AUTOSAR XML (schema 00047)
package /DBCImport/CANTP
  can tp config CanTpConfig_BCAN: communication-cluster=BCAN, can-tp-ecu=WPC
    can tp channel CanTpChannel0: channel-id=0, channel-mode=HALF-DUPLEX-MODE
    can tp channel CanTpChannel1: channel-id=1, channel-mode=HALF-DUPLEX-MODE
    tp-connections:
      addressing-format=STANDARD, can-tp-channel=CanTpChannel0, data-pdu=NPdu_BCAN_WPC_GST, flow-control-pdu=NPdu_BCAN_GST_WPC, max-block-size=0, padding-activation=true, ta-type=PHYSICAL-CAN-FD, tp-sdu=DcmIPdu_BCAN_WPC_GST
      addressing-format=STANDARD, can-tp-channel=CanTpChannel0, data-pdu=NPdu_BCAN_GST_WPC, flow-control-pdu=NPdu_BCAN_WPC_GST, max-block-size=0, padding-activation=true, ta-type=PHYSICAL-CAN-FD, tp-sdu=DcmIPdu_BCAN_GST_WPC
      addressing-format=STANDARD, can-tp-channel=CanTpChannel1, data-pdu=NPdu_BCAN_GST_ALL, max-block-size=0, padding-activation=true, ta-type=FUNCTIONAL-CAN-FD, tp-sdu=DcmIPdu_BCAN_GST_ALL
    can tp node WPC: connector=Conn_WPC_BCAN
package /DBCImport/NMCONFIG
  nm config NmConfig_BCAN
    can nm cluster CanNmCluster_BCAN: communication-cluster=BCAN, nm-pnc-participation=true, nm-msg-cycle-time=0.1, nm-network-timeout=1.0, nm-repeat-message-time=1.2, nm-wait-bus-sleep-time=1.5
      can nm node CanNmNode_BCAN:
        nm-node-id=158
        rx-nm-pdu=[NmPdu_BCAN_NM_SHVU_CCS_FD, NmPdu_BCAN_NM_ARS_FD, NmPdu_BCAN_NM_WPC2_FD, NmPdu_BCAN_NM_SCM_FD, NmPdu_BCAN_NM_SHVU_FRNT_FD, NmPdu_BCAN_NM_FLLR_FD, NmPdu_BCAN_NM_GW_SAU_DRV_FD, NmPdu_BCAN_NM_ATS_FD, NmPdu_BCAN_NM_PSB_FD, NmPdu_BCAN_NM_GW_PSU_RR_FD, NmPdu_BCAN_NM_SHVU_RL_FD, NmPdu_BCAN_NM_RWPC_FD, NmPdu_BCAN_NM_CGW_CCU, NmPdu_BCAN_NM_OHCL_FD, NmPdu_BCAN_NM_SHVU_REAR_FD, NmPdu_BCAN_NM_BLTN_CAM_FD, NmPdu_BCAN_NM_GW_PSU_DRV_FD, NmPdu_BCAN_NM_FCS_FD, NmPdu_BCAN_NM_GW_PSU_AST_FD, NmPdu_BCAN_NM_GW_PSU_3RD_FD, NmPdu_BCAN_NM_RCS_FD, NmPdu_BCAN_NM_RCM_FD, NmPdu_BCAN_NM_GW_PSU_RL_FD, NmPdu_BCAN_NM_SHVU_RR_FD, NmPdu_BCAN_NM_SHVU_3RD_FD, NmPdu_BCAN_NM_SGU_FD, NmPdu_BCAN_NM_DCM_FD]
        tx-nm-pdu=NmPdu_BCAN_NM_WPC_FD
        nm-range-config={lower-can-id=402391040, upper-can-id=402391294}
package /DBCImport/SWCComposition
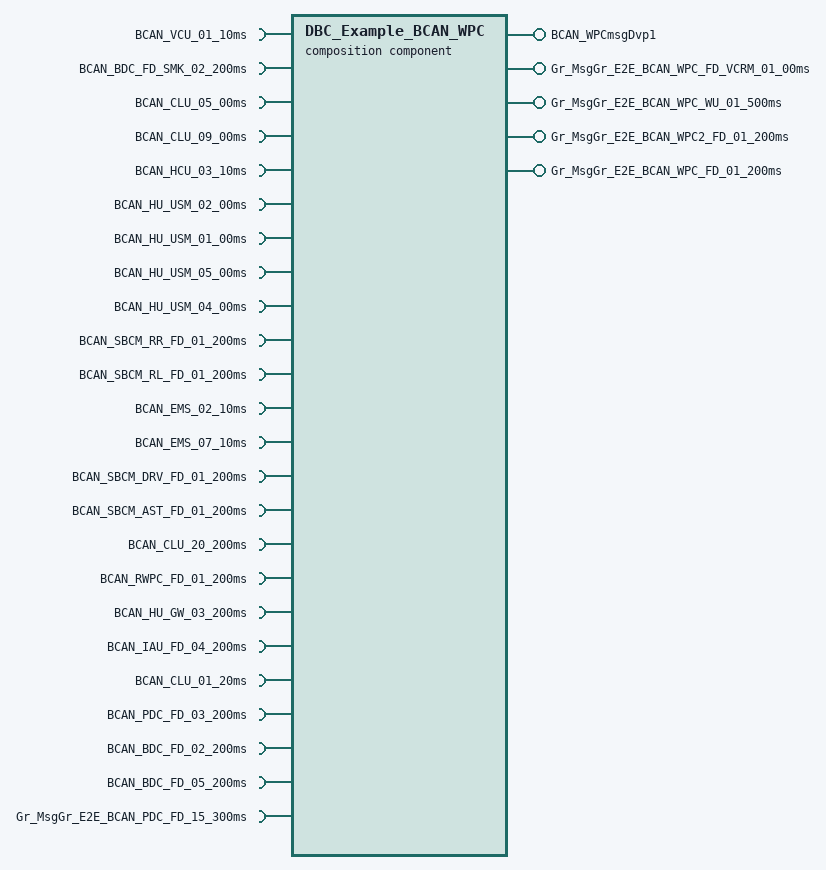
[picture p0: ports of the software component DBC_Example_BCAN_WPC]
  composition sw component type DBC_Example_BCAN_WPC
    5 x provide port:
      BCAN_WPCmsgDvp1: provided-interface=BCAN_WPCmsgDvp1
      Gr_MsgGr_E2E_BCAN_WPC_FD_VCRM_01_00ms: provided-interface=Gr_MsgGr_E2E_BCAN_WPC_FD_VCRM_01_00ms
      Gr_MsgGr_E2E_BCAN_WPC_WU_01_500ms: provided-interface=Gr_MsgGr_E2E_BCAN_WPC_WU_01_500ms
      Gr_MsgGr_E2E_BCAN_WPC2_FD_01_200ms: provided-interface=Gr_MsgGr_E2E_BCAN_WPC2_FD_01_200ms
      Gr_MsgGr_E2E_BCAN_WPC_FD_01_200ms: provided-interface=Gr_MsgGr_E2E_BCAN_WPC_FD_01_200ms
    24 x require port:
      BCAN_VCU_01_10ms: required-interface=BCAN_VCU_01_10ms
      BCAN_BDC_FD_SMK_02_200ms: required-interface=BCAN_BDC_FD_SMK_02_200ms
      BCAN_CLU_05_00ms: required-interface=BCAN_CLU_05_00ms
      BCAN_CLU_09_00ms: required-interface=BCAN_CLU_09_00ms
      BCAN_HCU_03_10ms: required-interface=BCAN_HCU_03_10ms
      BCAN_HU_USM_02_00ms: required-interface=BCAN_HU_USM_02_00ms
      BCAN_HU_USM_01_00ms: required-interface=BCAN_HU_USM_01_00ms
      BCAN_HU_USM_05_00ms: required-interface=BCAN_HU_USM_05_00ms
      BCAN_HU_USM_04_00ms: required-interface=BCAN_HU_USM_04_00ms
      BCAN_SBCM_RR_FD_01_200ms: required-interface=BCAN_SBCM_RR_FD_01_200ms
      BCAN_SBCM_RL_FD_01_200ms: required-interface=BCAN_SBCM_RL_FD_01_200ms
      BCAN_EMS_02_10ms: required-interface=BCAN_EMS_02_10ms
      BCAN_EMS_07_10ms: required-interface=BCAN_EMS_07_10ms
      BCAN_SBCM_DRV_FD_01_200ms: required-interface=BCAN_SBCM_DRV_FD_01_200ms
      BCAN_SBCM_AST_FD_01_200ms: required-interface=BCAN_SBCM_AST_FD_01_200ms
      BCAN_CLU_20_200ms: required-interface=BCAN_CLU_20_200ms
      BCAN_RWPC_FD_01_200ms: required-interface=BCAN_RWPC_FD_01_200ms
      BCAN_HU_GW_03_200ms: required-interface=BCAN_HU_GW_03_200ms
      BCAN_IAU_FD_04_200ms: required-interface=BCAN_IAU_FD_04_200ms
      BCAN_CLU_01_20ms: required-interface=BCAN_CLU_01_20ms
      BCAN_PDC_FD_03_200ms: required-interface=BCAN_PDC_FD_03_200ms
      BCAN_BDC_FD_02_200ms: required-interface=BCAN_BDC_FD_02_200ms
      BCAN_BDC_FD_05_200ms: required-interface=BCAN_BDC_FD_05_200ms
      Gr_MsgGr_E2E_BCAN_PDC_FD_15_300ms: required-interface=Gr_MsgGr_E2E_BCAN_PDC_FD_15_300ms
package /DBCImport/CLUSTERS
  can cluster BCAN: baudrate=500000, protocol-name=CAN, speed=500
    can physical channel BCAN: comm-connectors=Conn_WPC_BCAN
      frame CanFrame_BCAN_WPCmsgDvp1: id 0x686, frame-length=64, can-addressing-mode=STANDARD, can-fd-frame-support=true
        pdu ISignalIPdu_BCAN_WPCmsgDvp1: length=64, minimum-delay=0.02, transmission-mode-true-timing=event-controlled-timing={number-of-repetitions=3, repetition-period=0.04}
          signal ISignal_BCAN_WPCmsgDvp1_WPCmsgDvp1DataByte00: start 0, 8 bit, little-endian, init-value=0, base-type=uint8, compu {phys=raw for raw 0}, transfer-property=PENDING
          signal ISignal_BCAN_WPCmsgDvp1_WPCmsgDvp1DataByte01: start 8, 8 bit, little-endian, init-value=0, base-type=uint8, compu {phys=raw for raw 0}, transfer-property=PENDING
          signal ISignal_BCAN_WPCmsgDvp1_WPCmsgDvp1DataByte02: start 16, 8 bit, little-endian, init-value=0, base-type=uint8, compu {phys=raw for raw 0}, transfer-property=PENDING
          signal ISignal_BCAN_WPCmsgDvp1_WPCmsgDvp1DataByte03: start 24, 8 bit, little-endian, init-value=0, base-type=uint8, compu {phys=raw for raw 0}, transfer-property=PENDING
          signal ISignal_BCAN_WPCmsgDvp1_WPCmsgDvp1DataByte04: start 32, 8 bit, little-endian, init-value=0, base-type=uint8, compu {phys=raw for raw 0}, transfer-property=PENDING
          signal ISignal_BCAN_WPCmsgDvp1_WPCmsgDvp1DataByte05: start 40, 8 bit, little-endian, init-value=0, base-type=uint8, compu {phys=raw for raw 0}, transfer-property=PENDING
          signal ISignal_BCAN_WPCmsgDvp1_WPCmsgDvp1DataByte06: start 48, 8 bit, little-endian, init-value=0, base-type=uint8, compu {phys=raw for raw 0}, transfer-property=PENDING
          signal ISignal_BCAN_WPCmsgDvp1_WPCmsgDvp1DataByte07: start 56, 8 bit, little-endian, init-value=0, base-type=uint8, compu {phys=raw for raw 0}, transfer-property=PENDING
          signal ISignal_BCAN_WPCmsgDvp1_WPCmsgDvp1DataByte08: start 64, 8 bit, little-endian, init-value=0, base-type=uint8, compu {phys=raw for raw 0}, transfer-property=PENDING
          signal ISignal_BCAN_WPCmsgDvp1_WPCmsgDvp1DataByte09: start 72, 8 bit, little-endian, init-value=0, base-type=uint8, compu {phys=raw for raw 0}, transfer-property=PENDING
          signal ISignal_BCAN_WPCmsgDvp1_WPCmsgDvp1DataByte10: start 80, 8 bit, little-endian, init-value=0, base-type=uint8, compu {phys=raw for raw 0}, transfer-property=PENDING
          signal ISignal_BCAN_WPCmsgDvp1_WPCmsgDvp1DataByte11: start 88, 8 bit, little-endian, init-value=0, base-type=uint8, compu {phys=raw for raw 0}, transfer-property=PENDING
          signal ISignal_BCAN_WPCmsgDvp1_WPCmsgDvp1DataByte12: start 96, 8 bit, little-endian, init-value=0, base-type=uint8, compu {phys=raw for raw 0}, transfer-property=PENDING
          signal ISignal_BCAN_WPCmsgDvp1_WPCmsgDvp1DataByte13: start 104, 8 bit, little-endian, init-value=0, base-type=uint8, compu {phys=raw for raw 0}, transfer-property=PENDING
          signal ISignal_BCAN_WPCmsgDvp1_WPCmsgDvp1DataByte14: start 112, 8 bit, little-endian, init-value=0, base-type=uint8, compu {phys=raw for raw 0}, transfer-property=PENDING
          signal ISignal_BCAN_WPCmsgDvp1_WPCmsgDvp1DataByte15: start 120, 8 bit, little-endian, init-value=0, base-type=uint8, compu {phys=raw for raw 0}, transfer-property=PENDING
          signal ISignal_BCAN_WPCmsgDvp1_WPCmsgDvp1DataByte16: start 128, 8 bit, little-endian, init-value=0, base-type=uint8, compu {phys=raw for raw 0}, transfer-property=PENDING
          signal ISignal_BCAN_WPCmsgDvp1_WPCmsgDvp1DataByte17: start 136, 8 bit, little-endian, init-value=0, base-type=uint8, compu {phys=raw for raw 0}, transfer-property=PENDING
          signal ISignal_BCAN_WPCmsgDvp1_WPCmsgDvp1DataByte18: start 144, 8 bit, little-endian, init-value=0, base-type=uint8, compu {phys=raw for raw 0}, transfer-property=PENDING
          signal ISignal_BCAN_WPCmsgDvp1_WPCmsgDvp1DataByte19: start 152, 8 bit, little-endian, init-value=0, base-type=uint8, compu {phys=raw for raw 0}, transfer-property=PENDING
          signal ISignal_BCAN_WPCmsgDvp1_WPCmsgDvp1DataByte20: start 160, 8 bit, little-endian, init-value=0, base-type=uint8, compu {phys=raw for raw 0}, transfer-property=PENDING
          signal ISignal_BCAN_WPCmsgDvp1_WPCmsgDvp1DataByte21: start 168, 8 bit, little-endian, init-value=0, base-type=uint8, compu {phys=raw for raw 0}, transfer-property=PENDING
          signal ISignal_BCAN_WPCmsgDvp1_WPCmsgDvp1DataByte22: start 176, 8 bit, little-endian, init-value=0, base-type=uint8, compu {phys=raw for raw 0}, transfer-property=PENDING
          signal ISignal_BCAN_WPCmsgDvp1_WPCmsgDvp1DataByte23: start 184, 8 bit, little-endian, init-value=0, base-type=uint8, compu {phys=raw for raw 0}, transfer-property=PENDING
          signal ISignal_BCAN_WPCmsgDvp1_WPCmsgDvp1DataByte24: start 192, 8 bit, little-endian, init-value=0, base-type=uint8, compu {phys=raw for raw 0}, transfer-property=PENDING
          signal ISignal_BCAN_WPCmsgDvp1_WPCmsgDvp1DataByte25: start 200, 8 bit, little-endian, init-value=0, base-type=uint8, compu {phys=raw for raw 0}, transfer-property=PENDING
          signal ISignal_BCAN_WPCmsgDvp1_WPCmsgDvp1DataByte26: start 208, 8 bit, little-endian, init-value=0, base-type=uint8, compu {phys=raw for raw 0}, transfer-property=PENDING
          signal ISignal_BCAN_WPCmsgDvp1_WPCmsgDvp1DataByte27: start 216, 8 bit, little-endian, init-value=0, base-type=uint8, compu {phys=raw for raw 0}, transfer-property=PENDING
          signal ISignal_BCAN_WPCmsgDvp1_WPCmsgDvp1DataByte28: start 224, 8 bit, little-endian, init-value=0, base-type=uint8, compu {phys=raw for raw 0}, transfer-property=PENDING
          signal ISignal_BCAN_WPCmsgDvp1_WPCmsgDvp1DataByte29: start 232, 8 bit, little-endian, init-value=0, base-type=uint8, compu {phys=raw for raw 0}, transfer-property=PENDING
          signal ISignal_BCAN_WPCmsgDvp1_WPCmsgDvp1DataByte30: start 240, 8 bit, little-endian, init-value=0, base-type=uint8, compu {phys=raw for raw 0}, transfer-property=PENDING
          signal ISignal_BCAN_WPCmsgDvp1_WPCmsgDvp1DataByte31: start 248, 8 bit, little-endian, init-value=0, base-type=uint8, compu {phys=raw for raw 0}, transfer-property=PENDING
          signal ISignal_BCAN_WPCmsgDvp1_WPCmsgDvp1DataByte32: start 256, 8 bit, little-endian, init-value=0, base-type=uint8, compu {phys=raw for raw 0}, transfer-property=PENDING
          signal ISignal_BCAN_WPCmsgDvp1_WPCmsgDvp1DataByte33: start 264, 8 bit, little-endian, init-value=0, base-type=uint8, compu {phys=raw for raw 0}, transfer-property=PENDING
          signal ISignal_BCAN_WPCmsgDvp1_WPCmsgDvp1DataByte34: start 272, 8 bit, little-endian, init-value=0, base-type=uint8, compu {phys=raw for raw 0}, transfer-property=PENDING
          signal ISignal_BCAN_WPCmsgDvp1_WPCmsgDvp1DataByte35: start 280, 8 bit, little-endian, init-value=0, base-type=uint8, compu {phys=raw for raw 0}, transfer-property=PENDING
          signal ISignal_BCAN_WPCmsgDvp1_WPCmsgDvp1DataByte36: start 288, 8 bit, little-endian, init-value=0, base-type=uint8, compu {phys=raw for raw 0}, transfer-property=PENDING
          signal ISignal_BCAN_WPCmsgDvp1_WPCmsgDvp1DataByte37: start 296, 8 bit, little-endian, init-value=0, base-type=uint8, compu {phys=raw for raw 0}, transfer-property=PENDING
          signal ISignal_BCAN_WPCmsgDvp1_WPCmsgDvp1DataByte38: start 304, 8 bit, little-endian, init-value=0, base-type=uint8, compu {phys=raw for raw 0}, transfer-property=PENDING
          signal ISignal_BCAN_WPCmsgDvp1_WPCmsgDvp1DataByte39: start 312, 8 bit, little-endian, init-value=0, base-type=uint8, compu {phys=raw for raw 0}, transfer-property=PENDING
          signal ISignal_BCAN_WPCmsgDvp1_WPCmsgDvp1DataByte40: start 320, 8 bit, little-endian, init-value=0, base-type=uint8, compu {phys=raw for raw 0}, transfer-property=PENDING
          signal ISignal_BCAN_WPCmsgDvp1_WPCmsgDvp1DataByte41: start 328, 8 bit, little-endian, init-value=0, base-type=uint8, compu {phys=raw for raw 0}, transfer-property=PENDING
          signal ISignal_BCAN_WPCmsgDvp1_WPCmsgDvp1DataByte42: start 336, 8 bit, little-endian, init-value=0, base-type=uint8, compu {phys=raw for raw 0}, transfer-property=PENDING
          signal ISignal_BCAN_WPCmsgDvp1_WPCmsgDvp1DataByte43: start 344, 8 bit, little-endian, init-value=0, base-type=uint8, compu {phys=raw for raw 0}, transfer-property=PENDING
          signal ISignal_BCAN_WPCmsgDvp1_WPCmsgDvp1DataByte44: start 352, 8 bit, little-endian, init-value=0, base-type=uint8, compu {phys=raw for raw 0}, transfer-property=PENDING
          signal ISignal_BCAN_WPCmsgDvp1_WPCmsgDvp1DataByte45: start 360, 8 bit, little-endian, init-value=0, base-type=uint8, compu {phys=raw for raw 0}, transfer-property=PENDING
          signal ISignal_BCAN_WPCmsgDvp1_WPCmsgDvp1DataByte46: start 368, 8 bit, little-endian, init-value=0, base-type=uint8, compu {phys=raw for raw 0}, transfer-property=PENDING
          signal ISignal_BCAN_WPCmsgDvp1_WPCmsgDvp1DataByte47: start 376, 8 bit, little-endian, init-value=0, base-type=uint8, compu {phys=raw for raw 0}, transfer-property=PENDING
          signal ISignal_BCAN_WPCmsgDvp1_WPCmsgDvp1DataByte48: start 384, 8 bit, little-endian, init-value=0, base-type=uint8, compu {phys=raw for raw 0}, transfer-property=PENDING
          signal ISignal_BCAN_WPCmsgDvp1_WPCmsgDvp1DataByte49: start 392, 8 bit, little-endian, init-value=0, base-type=uint8, compu {phys=raw for raw 0}, transfer-property=PENDING
          signal ISignal_BCAN_WPCmsgDvp1_WPCmsgDvp1DataByte50: start 400, 8 bit, little-endian, init-value=0, base-type=uint8, compu {phys=raw for raw 0}, transfer-property=PENDING
          signal ISignal_BCAN_WPCmsgDvp1_WPCmsgDvp1DataByte51: start 408, 8 bit, little-endian, init-value=0, base-type=uint8, compu {phys=raw for raw 0}, transfer-property=PENDING
          signal ISignal_BCAN_WPCmsgDvp1_WPCmsgDvp1DataByte52: start 416, 8 bit, little-endian, init-value=0, base-type=uint8, compu {phys=raw for raw 0}, transfer-property=PENDING
          signal ISignal_BCAN_WPCmsgDvp1_WPCmsgDvp1DataByte53: start 424, 8 bit, little-endian, init-value=0, base-type=uint8, compu {phys=raw for raw 0}, transfer-property=PENDING
          signal ISignal_BCAN_WPCmsgDvp1_WPCmsgDvp1DataByte54: start 432, 8 bit, little-endian, init-value=0, base-type=uint8, compu {phys=raw for raw 0}, transfer-property=PENDING
          signal ISignal_BCAN_WPCmsgDvp1_WPCmsgDvp1DataByte55: start 440, 8 bit, little-endian, init-value=0, base-type=uint8, compu {phys=raw for raw 0}, transfer-property=PENDING
          signal ISignal_BCAN_WPCmsgDvp1_WPCmsgDvp1DataByte56: start 448, 8 bit, little-endian, init-value=0, base-type=uint8, compu {phys=raw for raw 0}, transfer-property=PENDING
          signal ISignal_BCAN_WPCmsgDvp1_WPCmsgDvp1DataByte57: start 456, 8 bit, little-endian, init-value=0, base-type=uint8, compu {phys=raw for raw 0}, transfer-property=PENDING
          signal ISignal_BCAN_WPCmsgDvp1_WPCmsgDvp1DataByte58: start 464, 8 bit, little-endian, init-value=0, base-type=uint8, compu {phys=raw for raw 0}, transfer-property=PENDING
          signal ISignal_BCAN_WPCmsgDvp1_WPCmsgDvp1DataByte59: start 472, 8 bit, little-endian, init-value=0, base-type=uint8, compu {phys=raw for raw 0}, transfer-property=PENDING
          signal ISignal_BCAN_WPCmsgDvp1_WPCmsgDvp1DataByte60: start 480, 8 bit, little-endian, init-value=0, base-type=uint8, compu {phys=raw for raw 0}, transfer-property=PENDING
          signal ISignal_BCAN_WPCmsgDvp1_WPCmsgDvp1DataByte61: start 488, 8 bit, little-endian, init-value=0, base-type=uint8, compu {phys=raw for raw 0}, transfer-property=PENDING
          signal ISignal_BCAN_WPCmsgDvp1_WPCmsgDvp1DataByte62: start 496, 8 bit, little-endian, init-value=0, base-type=uint8, compu {phys=raw for raw 0}, transfer-property=PENDING
          signal ISignal_BCAN_WPCmsgDvp1_WPCmsgDvp1DataByte63: start 504, 8 bit, little-endian, init-value=0, base-type=uint8, compu {phys=raw for raw 0}, transfer-property=TRIGGERED
      frame CanFrame_BCAN_VCU_01_10ms: id 0x35, frame-length=32, can-addressing-mode=STANDARD, can-fd-frame-support=true  # [P] Periodic
        pdu ISignalIPdu_BCAN_VCU_01_10ms: length=32, minimum-delay=0.02, transmission-mode-true-timing=cyclic-timing={time-offset=0.0, time-period=0.05}
          signal ISignal_BCAN_VCU_01_10ms_VCU_EvDrvRdySta: start 28, 2 bit, little-endian, init-value=0, base-type=uint8, compu {phys=raw for raw 0..3}, transfer-property=PENDING  # VCU_EvDriveReadyStatus ##2G##VCU - VCU1 - CF_Vcu_EvRdy
          signal ISignal_BCAN_VCU_01_10ms_VCU_GearPosSta: start 32, 4 bit, little-endian, init-value=9, base-type=uint8, compu {phys=raw for raw 0..15}, transfer-property=PENDING  # VCU_GearPositionStatus ##2G##VCU - VCU1 - CF_Vcu_GarSelDisp
      frame CanFrame_BCAN_WPC_FD_VCRM_01_00ms: id 0x21F, frame-length=16, can-addressing-mode=STANDARD, can-fd-frame-support=true  # [EC] On Event and On Change
        pdu ISignalIPdu_BCAN_WPC_FD_VCRM_01_00ms: length=16, minimum-delay=0.02, transmission-mode-true-timing=event-controlled-timing={number-of-repetitions=3, repetition-period=0.04}
          signal ISignal_BCAN_WPC_FD_VCRM_01_00ms_WPC_FD_VCRM_Crc1Val: start 0, 16 bit, little-endian, init-value=65535, base-type=uint16, compu {phys=raw for raw 0}, transfer-property=TRIGGERED-ON-CHANGE  # WPC_FD_VCRM_CyclicRedundancyCheck1Value
          signal ISignal_BCAN_WPC_FD_VCRM_01_00ms_WPC_FD_VCRM_AlvCnt1Val: start 16, 8 bit, little-endian, init-value=0, base-type=uint8, compu {phys=raw for raw 0}, transfer-property=TRIGGERED-ON-CHANGE  # WPC_FD_VCRM_AliveCounter1Value
          signal ISignal_BCAN_WPC_FD_VCRM_01_00ms_WPC_PhnUsingTime: start 24, 8 bit, little-endian, init-value=0, base-type=uint8, compu {phys=raw for raw 0; unit Min}, unit=Min, transfer-property=TRIGGERED-ON-CHANGE  # Charging time after IGN ON
          signal ISignal_BCAN_WPC_FD_VCRM_01_00ms_WPC_PhnChargingCompleteCnt: start 32, 4 bit, little-endian, init-value=0, base-type=uint8, compu {phys=raw for raw 0}, transfer-property=TRIGGERED-ON-CHANGE  # Number of fully charged event after IGN on
          signal ISignal_BCAN_WPC_FD_VCRM_01_00ms_WPC_EPPChargingCnt: start 36, 4 bit, little-endian, init-value=0, base-type=uint8, compu {phys=raw for raw 0}, transfer-property=TRIGGERED-ON-CHANGE  # EPP TYPE charging count
          signal ISignal_BCAN_WPC_FD_VCRM_01_00ms_WPC_MPPChargingCnt: start 40, 4 bit, little-endian, init-value=0, base-type=uint8, compu {phys=raw for raw 0}, transfer-property=TRIGGERED-ON-CHANGE  # MPP TYPE charging count
          signal ISignal_BCAN_WPC_FD_VCRM_01_00ms_WPC_DigitalKeyAuth: start 44, 1 bit, little-endian, init-value=0, base-type=boolean, compu {phys=raw for raw 0}, transfer-property=TRIGGERED-ON-CHANGE  # starting the car authentication by Digital key
          signal ISignal_BCAN_WPC_FD_VCRM_01_00ms_WPC_DigitalKeyDevice: start 45, 3 bit, little-endian, init-value=0, base-type=uint8, compu {phys=raw for raw 0}, transfer-property=TRIGGERED-ON-CHANGE  # Digital key device type
          signal ISignal_BCAN_WPC_FD_VCRM_01_00ms_WPC_PhnChargingErrCnt: start 48, 6 bit, little-endian, init-value=0, base-type=uint8, compu {phys=raw for raw 0}, transfer-property=TRIGGERED-ON-CHANGE  # Phone Charging Error Count
          signal ISignal_BCAN_WPC_FD_VCRM_01_00ms_WPC_ThermalSnsrMaxTemp: start 54, 8 bit, little-endian, init-value=0, base-type=uint8, compu {phys=raw for raw 0}, transfer-property=TRIGGERED-ON-CHANGE  # Thermal Sensor Max Temperature
          signal ISignal_BCAN_WPC_FD_VCRM_01_00ms_WPC_CANBusOffDTC: start 62, 2 bit, little-endian, init-value=0, base-type=uint8, compu {phys=raw for raw 0}, transfer-property=TRIGGERED-ON-CHANGE  # DTC Monitoring
          signal ISignal_BCAN_WPC_FD_VCRM_01_00ms_WPC_LocalCANBusOffDTC: start 64, 2 bit, little-endian, init-value=0, base-type=uint8, compu {phys=raw for raw 0}, transfer-property=TRIGGERED-ON-CHANGE  # DTC Monitoring
          signal ISignal_BCAN_WPC_FD_VCRM_01_00ms_WPC_TempSnsrFltDTC: start 66, 2 bit, little-endian, init-value=0, base-type=uint8, compu {phys=raw for raw 0}, transfer-property=TRIGGERED-ON-CHANGE  # DTC Monitoring
          signal ISignal_BCAN_WPC_FD_VCRM_01_00ms_WPC_FANFltDTC: start 68, 2 bit, little-endian, init-value=0, base-type=uint8, compu {phys=raw for raw 0}, transfer-property=TRIGGERED-ON-CHANGE  # DTC Monitoring
          signal ISignal_BCAN_WPC_FD_VCRM_01_00ms_WPC_InternalECUErrDTC: start 70, 2 bit, little-endian, init-value=0, base-type=uint8, compu {phys=raw for raw 0}, transfer-property=TRIGGERED-ON-CHANGE  # DTC Monitoring
          signal ISignal_BCAN_WPC_FD_VCRM_01_00ms_WPC_FD_VCRM_01_00ms_E2EReserved: start 120, 8 bit, little-endian, init-value=0, base-type=uint8, compu {phys=0 for raw NaN}
          mapping MsgGr_BCAN_WPC_FD_VCRM_01_00ms: i-signal-group=MsgGr_E2E_BCAN_WPC_FD_VCRM_01_00ms, transfer-property=TRIGGERED-ON-CHANGE
      frame CanFrame_BCAN_BDC_FD_SMK_02_200ms: id 0x401, frame-length=32, can-addressing-mode=STANDARD, can-fd-frame-support=true  # [PE] Periodic and On Event
        pdu ISignalIPdu_BCAN_BDC_FD_SMK_02_200ms: length=32, minimum-delay=0.02, transmission-mode-true-timing={cyclic-timing={time-offset=0.03, time-period=0.2}, event-controlled-timing={number-of-repetitions=3, repetition-period=0.04}}
          signal ISignal_BCAN_BDC_FD_SMK_02_200ms_LFAnt_SrchSta: start 88, 2 bit, little-endian, init-value=0, base-type=uint8, compu {phys=raw for raw 0}, transfer-property=TRIGGERED-ON-CHANGE  # LFAntenna_SearchingStatus ##2G##SMK - SMKmsg19 - C_LFSearchingOn
      frame CanFrame_BCAN_WPC_WU_01_500ms: id 0x1EC7B001, frame-length=16, can-addressing-mode=EXTENDED, can-fd-frame-support=true  # [PE] Periodic and On Event
        pdu ISignalIPdu_BCAN_WPC_WU_01_500ms: length=16, minimum-delay=0.02, transmission-mode-true-timing={cyclic-timing={time-offset=0.0, time-period=1.0}, event-controlled-timing={number-of-repetitions=3, repetition-period=0.04}}
          signal ISignal_BCAN_WPC_WU_01_500ms_WPC_WU_Crc1Val: start 0, 16 bit, little-endian, init-value=65535, base-type=uint16, compu {phys=raw for raw 0}, transfer-property=TRIGGERED-ON-CHANGE  # WPC_WU_CyclicRedundancyCheck1Value
          signal ISignal_BCAN_WPC_WU_01_500ms_WPC_WU_AlvCnt1Val: start 16, 8 bit, little-endian, init-value=0, base-type=uint8, compu {phys=raw for raw 0}, transfer-property=TRIGGERED-ON-CHANGE  # WPC_WU_AliveCounter1Value
          signal ISignal_BCAN_WPC_WU_01_500ms_WPC_WU_NM_B2: start 24, 1 bit, little-endian, init-value=0, base-type=boolean, compu {phys=raw for raw 0}, transfer-property=TRIGGERED-ON-CHANGE  # WPC Wake Up by NM in B2
          signal ISignal_BCAN_WPC_WU_01_500ms_WPC_WU_NM_BDCLocal: start 25, 1 bit, little-endian, init-value=0, base-type=boolean, compu {phys=raw for raw 0}, transfer-property=TRIGGERED-ON-CHANGE  # WPC Wake Up by NM in BDCLocal
          signal ISignal_BCAN_WPC_WU_01_500ms_WPC_WU_PWR_ACC: start 32, 1 bit, little-endian, init-value=0, base-type=boolean, compu {phys=raw for raw 0}, transfer-property=TRIGGERED-ON-CHANGE  # WPC Wake Up by Power State Input with ACC
          signal ISignal_BCAN_WPC_WU_01_500ms_WPC_WU_PWR_IGN1: start 33, 1 bit, little-endian, init-value=0, base-type=boolean, compu {phys=raw for raw 0}, transfer-property=TRIGGERED-ON-CHANGE  # WPC Wake Up by Power State Input with IGN1
          signal ISignal_BCAN_WPC_WU_01_500ms_WPC_WU_R_DrvDoorSw: start 40, 1 bit, little-endian, init-value=0, base-type=boolean, compu {phys=raw for raw 0}, transfer-property=TRIGGERED-ON-CHANGE  # WPC Wake Up by Remote Message - DrvDoorSw
          signal ISignal_BCAN_WPC_WU_01_500ms_WPC_WU_R_B1CAN: start 41, 1 bit, little-endian, init-value=0, base-type=boolean, compu {phys=raw for raw 0}, transfer-property=TRIGGERED-ON-CHANGE  # WPC Wake Up by Remote Message - B1CAN
          signal ISignal_BCAN_WPC_WU_01_500ms_WPC_WU_R_BDCLocalCAN: start 42, 1 bit, little-endian, init-value=0, base-type=boolean, compu {phys=raw for raw 0}, transfer-property=TRIGGERED-ON-CHANGE  # WPC Wake Up by Remote Message - BDCLocalCAN
          signal ISignal_BCAN_WPC_WU_01_500ms_WPC_WU_R_Diag: start 43, 1 bit, little-endian, init-value=0, base-type=boolean, compu {phys=raw for raw 0}, transfer-property=TRIGGERED-ON-CHANGE  # WPC Wake Up by Remote Message - Diag
          signal ISignal_BCAN_WPC_WU_01_500ms_WPC_WU_R_IGNFallingTimer: start 44, 1 bit, little-endian, init-value=0, base-type=boolean, compu {phys=raw for raw 0}, transfer-property=TRIGGERED-ON-CHANGE  # WPC Wake Up by Remote Message - IGNFallingTimer
          signal ISignal_BCAN_WPC_WU_01_500ms_WPC_WU_01_500ms_E2EReserved: start 120, 8 bit, little-endian, init-value=0, base-type=uint8, compu {phys=0 for raw NaN}
          mapping MsgGr_BCAN_WPC_WU_01_500ms: i-signal-group=MsgGr_E2E_BCAN_WPC_WU_01_500ms, transfer-property=TRIGGERED-ON-CHANGE
      frame CanFrame_BCAN_CLU_05_00ms: id 0x4D1, frame-length=8, can-addressing-mode=STANDARD, can-fd-frame-support=true  # [EC] On Event and On Change
        pdu ISignalIPdu_BCAN_CLU_05_00ms: length=8, minimum-delay=0.02, transmission-mode-true-timing=event-controlled-timing={number-of-repetitions=3, repetition-period=0.04}
          signal ISignal_BCAN_CLU_05_00ms_USM_StaRst1Req: start 34, 2 bit, little-endian, init-value=0, base-type=uint8, compu {phys=raw for raw 0}, transfer-property=TRIGGERED-ON-CHANGE  # USM_StatusReset1Request
      frame CanFrame_BCAN_CLU_09_00ms: id 0x4DA, frame-length=8, can-addressing-mode=STANDARD, can-fd-frame-support=true  # [EC] On Event and On Change
        pdu ISignalIPdu_BCAN_CLU_09_00ms: length=8, minimum-delay=0.02, transmission-mode-true-timing=event-controlled-timing={number-of-repetitions=3, repetition-period=0.04}
          signal ISignal_BCAN_CLU_09_00ms_USM_WpcSetReq: start 34, 2 bit, little-endian, init-value=0, base-type=uint8, compu {phys=raw for raw 0}, transfer-property=TRIGGERED-ON-CHANGE  # USM_WpcSetRequest
      frame CanFrame_BCAN_PDC_FD_15_300ms: id 0x2E9, frame-length=32, can-addressing-mode=STANDARD, can-fd-frame-support=true  # [PE] Periodic and On Event
        pdu ISignalIPdu_BCAN_PDC_FD_15_300ms: length=32, minimum-delay=0.02, transmission-mode-true-timing={cyclic-timing={time-offset=0.0, time-period=0.3}, event-controlled-timing={number-of-repetitions=3, repetition-period=0.04}}
          signal ISignal_BCAN_PDC_FD_15_300ms_PDC_FD_Crc15Val: start 0, 16 bit, little-endian, init-value=65535, base-type=uint16, compu {phys=raw for raw 0}, transfer-property=TRIGGERED-ON-CHANGE  # PDC_FD_CyclicRedundancyCheck15Value
          signal ISignal_BCAN_PDC_FD_15_300ms_PDC_FD_AlvCnt15Val: start 16, 8 bit, little-endian, init-value=0, base-type=uint8, compu {phys=raw for raw 0}, transfer-property=TRIGGERED-ON-CHANGE  # PDC_FD_AliveCounter15Value
          signal ISignal_BCAN_PDC_FD_15_300ms_PDC_ResetPreWrngForOthers: start 42, 2 bit, little-endian, init-value=0, base-type=uint8, compu {phys=raw for raw 0}, transfer-property=TRIGGERED-ON-CHANGE  # This is a warning signal for reset. This signal is used for preparing sideeffect of reset by Receivers
          signal ISignal_BCAN_PDC_FD_15_300ms_PDC_ResetReqForOthers: start 46, 2 bit, little-endian, init-value=0, base-type=uint8, compu {phys=raw for raw 0}, transfer-property=TRIGGERED-ON-CHANGE  # This is a request signal for SW reset except for Gateway
          signal ISignal_BCAN_PDC_FD_15_300ms_PDC_ResetFuncOpt: start 48, 2 bit, little-endian, init-value=0, base-type=uint8, compu {phys=raw for raw 0}, transfer-property=TRIGGERED-ON-CHANGE  # This signal inform whether reset fucntion at PDC is appiled or not
          signal ISignal_BCAN_PDC_FD_15_300ms_PDC_FD_15_300ms_E2EReserved: start 248, 8 bit, little-endian, init-value=0, base-type=uint8, compu {phys=0 for raw NaN}
          mapping MsgGr_BCAN_PDC_FD_15_300ms: i-signal-group=MsgGr_E2E_BCAN_PDC_FD_15_300ms, transfer-property=TRIGGERED-ON-CHANGE
      frame CanFrame_BCAN_HCU_03_10ms: id 0xFA, frame-length=32, can-addressing-mode=STANDARD, can-fd-frame-support=true  # [P] Periodic
        pdu ISignalIPdu_BCAN_HCU_03_10ms: length=32, minimum-delay=0.02, transmission-mode-true-timing=cyclic-timing={time-offset=0.0, time-period=0.05}
          signal ISignal_BCAN_HCU_03_10ms_HCU_HevRdySta: start 70, 2 bit, little-endian, init-value=0, base-type=uint8, compu {phys=raw for raw 0}, transfer-property=PENDING  # HCU_HybridVehicleReadyStatus ##2G##HCU - HCU1 - CF_Hcu_HevRdy
      frame CanFrame_BCAN_HU_USM_02_00ms: id 0x112, frame-length=32, can-addressing-mode=STANDARD, can-fd-frame-support=true  # [EC] On Event and On Change
        pdu ISignalIPdu_BCAN_HU_USM_02_00ms: length=32, minimum-delay=0.02, transmission-mode-true-timing=event-controlled-timing={number-of-repetitions=3, repetition-period=0.04}
          signal ISignal_BCAN_HU_USM_02_00ms_CF_AVN_CluUSMReset: start 126, 2 bit, little-endian, init-value=0, base-type=uint8, compu {phys=raw for raw 0}, transfer-property=TRIGGERED-ON-CHANGE  # Request to reset all USM service
      frame CanFrame_BCAN_HU_USM_01_00ms: id 0x111, frame-length=32, can-addressing-mode=STANDARD, can-fd-frame-support=true  # [EC] On Event and On Change
        pdu ISignalIPdu_BCAN_HU_USM_01_00ms: length=32, minimum-delay=0.02, transmission-mode-true-timing=event-controlled-timing={number-of-repetitions=3, repetition-period=0.04}
          signal ISignal_BCAN_HU_USM_01_00ms_CF_Gway_WPCNValueSet: start 152, 2 bit, little-endian, init-value=0, base-type=uint8, compu {phys=raw for raw 0}, transfer-property=TRIGGERED-ON-CHANGE  # Request to set Wireless Phone Charging mode
      frame CanFrame_BCAN_HU_USM_05_00ms: id 0x116, frame-length=32, can-addressing-mode=STANDARD, can-fd-frame-support=true  # [EC] On Event and On Change
        pdu ISignalIPdu_BCAN_HU_USM_05_00ms: length=32, minimum-delay=0.02, transmission-mode-true-timing=event-controlled-timing={number-of-repetitions=3, repetition-period=0.04}
          signal ISignal_BCAN_HU_USM_05_00ms_CF_Gway_WPCAnimationNvalueSet: start 168, 3 bit, little-endian, init-value=0, base-type=uint8, compu {phys=raw for raw 0}, transfer-property=TRIGGERED-ON-CHANGE
      frame CanFrame_BCAN_HU_USM_04_00ms: id 0x114, frame-length=32, can-addressing-mode=STANDARD, can-fd-frame-support=true  # [EC] On Event and On Change
        pdu ISignalIPdu_BCAN_HU_USM_04_00ms: length=32, minimum-delay=0.02, transmission-mode-true-timing=event-controlled-timing={number-of-repetitions=3, repetition-period=0.04}
          signal ISignal_BCAN_HU_USM_04_00ms_CF_Gway_WPC2_NValueSet: start 245, 2 bit, little-endian, init-value=0, base-type=uint8, compu {phys=raw for raw 0}, transfer-property=TRIGGERED-ON-CHANGE
      frame CanFrame_BCAN_SBCM_RR_FD_01_200ms: id 0x33D, frame-length=24, can-addressing-mode=STANDARD, can-fd-frame-support=true  # [PE] Periodic and On Event
        pdu ISignalIPdu_BCAN_SBCM_RR_FD_01_200ms: length=24, minimum-delay=0.02, transmission-mode-true-timing={cyclic-timing={time-offset=0.0, time-period=0.2}, event-controlled-timing={number-of-repetitions=3, repetition-period=0.04}}
          signal ISignal_BCAN_SBCM_RR_FD_01_200ms_Warn_RrRtDrSwSta_SBCM: start 80, 2 bit, little-endian, init-value=0, base-type=uint8, compu {phys=raw for raw 0}, transfer-property=TRIGGERED-ON-CHANGE  # Warn_RearRightDoorSwitchStatus ##2G## - - C_RRDrSw,CF_Gway_RRDrSw,Warn_RrRtDrSwSta
      frame CanFrame_BCAN_SBCM_RL_FD_01_200ms: id 0x33E, frame-length=24, can-addressing-mode=STANDARD, can-fd-frame-support=true  # [PE] Periodic and On Event
        pdu ISignalIPdu_BCAN_SBCM_RL_FD_01_200ms: length=24, minimum-delay=0.02, transmission-mode-true-timing={cyclic-timing={time-offset=0.0, time-period=0.2}, event-controlled-timing={number-of-repetitions=3, repetition-period=0.04}}
          signal ISignal_BCAN_SBCM_RL_FD_01_200ms_Warn_RrLftDrSwSta_SBCM: start 80, 2 bit, little-endian, init-value=0, base-type=uint8, compu {phys=raw for raw 0}, transfer-property=TRIGGERED-ON-CHANGE  # Warn_RearLeftDoorSwitchStatus ##2G## - - C_RLDrSw,CF_Gway_RLDrSw,Warn_RrLftDrSwSta
      frame CanFrame_BCAN_EMS_02_10ms: id 0x100, frame-length=32, can-addressing-mode=STANDARD, can-fd-frame-support=true  # [P] Periodic
        pdu ISignalIPdu_BCAN_EMS_02_10ms: length=32, minimum-delay=0.02, transmission-mode-true-timing=cyclic-timing={time-offset=0.0, time-period=0.05}
          signal ISignal_BCAN_EMS_02_10ms_ENG_EngSta: start 61, 3 bit, little-endian, init-value=0, base-type=uint8, compu {phys=raw for raw 0}, transfer-property=PENDING  # ENG_EngineStatus ##2G##EMS - EMS16 - ENG_STAT
      frame CanFrame_BCAN_EMS_07_10ms: id 0x105, frame-length=32, can-addressing-mode=STANDARD, can-fd-frame-support=true  # [P] Periodic
        pdu ISignalIPdu_BCAN_EMS_07_10ms: length=32, minimum-delay=0.02, transmission-mode-true-timing=cyclic-timing={time-offset=0.0, time-period=0.05}
          signal ISignal_BCAN_EMS_07_10ms_HEV_EngOpSta: start 92, 3 bit, little-endian, init-value=0, base-type=uint8, compu {phys=raw for raw 0}, transfer-property=PENDING  # HEV_EngineOperatingStatus
      frame CanFrame_BCAN_SBCM_DRV_FD_01_200ms: id 0x32D, frame-length=32, can-addressing-mode=STANDARD, can-fd-frame-support=true  # [PE] Periodic and On Event
        pdu ISignalIPdu_BCAN_SBCM_DRV_FD_01_200ms: length=32, minimum-delay=0.02, transmission-mode-true-timing={cyclic-timing={time-offset=0.0, time-period=0.2}, event-controlled-timing={number-of-repetitions=3, repetition-period=0.04}}
          signal ISignal_BCAN_SBCM_DRV_FD_01_200ms_Warn_DrvDrSwSta_SBCM: start 84, 2 bit, little-endian, init-value=0, base-type=uint8, compu {phys=raw for raw 0}, transfer-property=TRIGGERED-ON-CHANGE  # DoorLock_DriverDoorSwitchStatus ##2G## - - C_DrvDrSw,CF_Gway_DrvDrSw,Warn_DrvDrSwSta
          signal ISignal_BCAN_SBCM_DRV_FD_01_200ms_Latch_TypeOption_DRV: start 100, 2 bit, little-endian, init-value=0, base-type=uint8, compu {phys=raw for raw 0}, transfer-property=TRIGGERED-ON-CHANGE
      frame CanFrame_BCAN_SBCM_AST_FD_01_200ms: id 0x32B, frame-length=32, can-addressing-mode=STANDARD, can-fd-frame-support=true  # [PE] Periodic and On Event
        pdu ISignalIPdu_BCAN_SBCM_AST_FD_01_200ms: length=32, minimum-delay=0.02, transmission-mode-true-timing={cyclic-timing={time-offset=0.0, time-period=0.2}, event-controlled-timing={number-of-repetitions=3, repetition-period=0.04}}
          signal ISignal_BCAN_SBCM_AST_FD_01_200ms_Warn_AsstDrSwSta_SBCM: start 84, 2 bit, little-endian, init-value=0, base-type=uint8, compu {phys=raw for raw 0}, transfer-property=TRIGGERED-ON-CHANGE  # Warn_AssistDoorSwitchStatus ##2G## - - C_AstDrSw,CF_Gway_AstDrSw,Warn_AsstDrSwSta
      frame CanFrame_BCAN_CLU_20_200ms: id 0x315, frame-length=16, can-addressing-mode=STANDARD, can-fd-frame-support=true  # [P] Periodic
        pdu ISignalIPdu_BCAN_CLU_20_200ms: length=16, minimum-delay=0.02, transmission-mode-true-timing=cyclic-timing={time-offset=0.0, time-period=0.2}
          signal ISignal_BCAN_CLU_20_200ms_CLU_ClusterUSM: start 49, 2 bit, little-endian, init-value=0, base-type=uint8, compu {phys=raw for raw 0}, transfer-property=PENDING
      frame CanFrame_BCAN_RWPC_FD_01_200ms: id 0x314, frame-length=16, can-addressing-mode=STANDARD, can-fd-frame-support=true  # [PE] Periodic and On Event
        pdu ISignalIPdu_BCAN_RWPC_FD_01_200ms: length=16, minimum-delay=0.02, transmission-mode-true-timing={cyclic-timing={time-offset=0.0, time-period=0.2}, event-controlled-timing={number-of-repetitions=3, repetition-period=0.04}}
          signal ISignal_BCAN_RWPC_FD_01_200ms_RWPC_IndSyncVal: start 104, 3 bit, little-endian, init-value=0, base-type=uint8, compu {phys=raw for raw 0}, transfer-property=TRIGGERED-ON-CHANGE
      frame CanFrame_BCAN_WPC_GST: id 0x72D, category=BASIC_CAN, frame-length=8, can-addressing-mode=STANDARD, can-fd-frame-support=true
        dcm i pdu DcmIPdu_BCAN_WPC_GST: length=64, diag-pdu-type=DIAG-RESPONSE
        n pdu NPdu_BCAN_WPC_GST: length=8, meta-data-length=0
      frame CanFrame_BCAN_HU_GW_03_200ms: id 0x366, frame-length=24, can-addressing-mode=STANDARD, can-fd-frame-support=true  # [PE] Periodic and On Event
        pdu ISignalIPdu_BCAN_HU_GW_03_200ms: length=24, minimum-delay=0.02, transmission-mode-true-timing={cyclic-timing={time-offset=0.05, time-period=0.2}, event-controlled-timing={number-of-repetitions=3, repetition-period=0.04}}
          signal ISignal_BCAN_HU_GW_03_200ms_CF_AVN_ProfileIDRValue: start 104, 4 bit, little-endian, init-value=15, base-type=uint8, compu {phys=raw for raw 0}, transfer-property=TRIGGERED-ON-CHANGE  # This signal is User ID value in H/Unit.
      frame CanFrame_BCAN_GST_WPC: id 0x725, frame-length=8, can-addressing-mode=STANDARD, can-fd-frame-support=true
        dcm i pdu DcmIPdu_BCAN_GST_WPC: length=8, diag-pdu-type=DIAG-REQUEST
        n pdu NPdu_BCAN_GST_WPC: length=8, meta-data-length=0
      frame CanFrame_BCAN_IAU_FD_04_200ms: id 0x351, frame-length=32, can-addressing-mode=STANDARD, can-fd-frame-support=true  # [PE] Periodic and On Event
        pdu ISignalIPdu_BCAN_IAU_FD_04_200ms: length=32, minimum-delay=0.02, transmission-mode-true-timing={cyclic-timing={time-offset=0.04, time-period=0.2}, event-controlled-timing={number-of-repetitions=3, repetition-period=0.04}}
          signal ISignal_BCAN_IAU_FD_04_200ms_IAU_ProfileIDRVal: start 74, 4 bit, little-endian, init-value=0, base-type=uint8, compu-method=ISignal_BCAN_IAU_FD_04_200ms_IAU_ProfileIDRVal, transfer-property=TRIGGERED-ON-CHANGE  # This signal Indicate the Current detected Profile ID by IAU.
          signal ISignal_BCAN_IAU_FD_04_200ms_IAU_DigitalKey2Opt: start 120, 3 bit, little-endian, init-value=0, base-type=uint8, compu {phys=raw for raw 0}, transfer-property=TRIGGERED-ON-CHANGE  # Digital Key2 Option Signal
      frame CanFrame_BCAN_WPC2_FD_01_200ms: id 0x392, frame-length=16, can-addressing-mode=STANDARD, can-fd-frame-support=true  # [PE] Periodic and On Event
        pdu ISignalIPdu_BCAN_WPC2_FD_01_200ms: length=16, minimum-delay=0.02, transmission-mode-true-timing={cyclic-timing={time-offset=0.0, time-period=0.2}, event-controlled-timing={number-of-repetitions=3, repetition-period=0.04}}
          signal ISignal_BCAN_WPC2_FD_01_200ms_WPC2_FD_Crc1Val: start 0, 16 bit, little-endian, init-value=65535, base-type=uint16, compu {phys=raw for raw 0}, transfer-property=TRIGGERED-ON-CHANGE  # WPC2_FD_CyclicRedundancyCheck1Value
          signal ISignal_BCAN_WPC2_FD_01_200ms_WPC2_FD_AlvCnt1Val: start 16, 8 bit, little-endian, init-value=0, base-type=uint8, compu {phys=raw for raw 0}, transfer-property=TRIGGERED-ON-CHANGE  # WPC2_FD_AliveCounter1Value
          signal ISignal_BCAN_WPC2_FD_01_200ms_USM_CmdWPC2Sta: start 64, 2 bit, little-endian, init-value=0, base-type=uint8, compu {phys=raw for raw 0}, transfer-property=TRIGGERED-ON-CHANGE  # USM_CommandWPC2Status
          signal ISignal_BCAN_WPC2_FD_01_200ms_WPC2_PhnLftWrngSta: start 66, 3 bit, little-endian, init-value=0, base-type=uint8, compu {phys=raw for raw 0}, transfer-property=TRIGGERED-ON-CHANGE  # WPC2_PhoneLeftWarningStatus
          signal ISignal_BCAN_WPC2_FD_01_200ms_WPC2_OptSta: start 76, 2 bit, little-endian, init-value=0, base-type=uint8, compu {0=Default, 1=Apply, 2=RESERVED, 3=Invalid, phys=raw for raw 0}, transfer-property=TRIGGERED-ON-CHANGE
          signal ISignal_BCAN_WPC2_FD_01_200ms_WPC2_SWVerMajor1: start 80, 7 bit, little-endian, init-value=0, base-type=uint8, compu {phys=raw for raw 0}, transfer-property=TRIGGERED-ON-CHANGE  # First Word(ASCII) in WPC2 S/W Ver
          signal ISignal_BCAN_WPC2_FD_01_200ms_WPC2_SWVerMinor1: start 88, 7 bit, little-endian, init-value=0, base-type=uint8, compu {phys=raw for raw 0}, transfer-property=TRIGGERED-ON-CHANGE  # Second Word(ASCII) in WPC2 S/W Ver
          signal ISignal_BCAN_WPC2_FD_01_200ms_WPC2_SWVerMinor2: start 96, 7 bit, little-endian, init-value=0, base-type=uint8, compu {phys=raw for raw 0}, transfer-property=TRIGGERED-ON-CHANGE  # Third Word(ASCII) in WPC2 S/W Ver
          signal ISignal_BCAN_WPC2_FD_01_200ms_WPC2_IndSyncVal: start 104, 3 bit, little-endian, init-value=0, base-type=uint8, compu {phys=raw for raw 0}, transfer-property=TRIGGERED-ON-CHANGE
          signal ISignal_BCAN_WPC2_FD_01_200ms_WPC2_ResetOpSta: start 110, 2 bit, little-endian, init-value=0, base-type=uint8, compu {phys=raw for raw 0}, transfer-property=TRIGGERED-ON-CHANGE  # This signal indicates whether the reset operation has been completed or not
          signal ISignal_BCAN_WPC2_FD_01_200ms_WPC2_FD_01_200ms_E2EReserved: start 120, 8 bit, little-endian, init-value=0, base-type=uint8, compu {phys=0 for raw NaN}
          mapping MsgGr_BCAN_WPC2_FD_01_200ms: i-signal-group=MsgGr_E2E_BCAN_WPC2_FD_01_200ms, transfer-property=TRIGGERED-ON-CHANGE
      frame CanFrame_BCAN_GST_ALL: id 0x7DF, frame-length=8, can-addressing-mode=STANDARD, can-fd-frame-support=true
        dcm i pdu DcmIPdu_BCAN_GST_ALL: length=8
        n pdu NPdu_BCAN_GST_ALL: length=8, meta-data-length=0
      frame CanFrame_BCAN_WPC_FD_01_200ms: id 0x391, frame-length=16, can-addressing-mode=STANDARD, can-fd-frame-support=true  # [PE] Periodic and On Event
        pdu ISignalIPdu_BCAN_WPC_FD_01_200ms: length=16, minimum-delay=0.02, transmission-mode-true-timing={cyclic-timing={time-offset=0.0, time-period=0.2}, event-controlled-timing={number-of-repetitions=3, repetition-period=0.04}}
          signal ISignal_BCAN_WPC_FD_01_200ms_WPC_FD_Crc1Val: start 0, 16 bit, little-endian, init-value=65535, base-type=uint16, compu {phys=raw for raw 0}, transfer-property=TRIGGERED-ON-CHANGE  # WPC_FD_CyclicRedundancyCheck1Value
          signal ISignal_BCAN_WPC_FD_01_200ms_WPC_FD_AlvCnt1Val: start 16, 8 bit, little-endian, init-value=0, base-type=uint8, compu {phys=raw for raw 0}, transfer-property=TRIGGERED-ON-CHANGE  # WPC_FD_AliveCounter1Value
          signal ISignal_BCAN_WPC_FD_01_200ms_USM_CmdWPCSta: start 64, 2 bit, little-endian, init-value=0, base-type=uint8, compu {phys=raw for raw 0}, transfer-property=TRIGGERED-ON-CHANGE  # USM_CommandWPCStatus
          signal ISignal_BCAN_WPC_FD_01_200ms_WPC_PhnLftWrngSta: start 66, 3 bit, little-endian, init-value=0, base-type=uint8, compu {phys=raw for raw 0}, transfer-property=TRIGGERED-ON-CHANGE  # WPC_PhoneLeftWarningStatus
          signal ISignal_BCAN_WPC_FD_01_200ms_WPC_DualWPCOptSta: start 76, 2 bit, little-endian, init-value=0, base-type=uint8, compu {phys=raw for raw 0}, transfer-property=TRIGGERED-ON-CHANGE
          signal ISignal_BCAN_WPC_FD_01_200ms_WPC_SWVerMajor1: start 80, 7 bit, little-endian, init-value=0, base-type=uint8, compu {phys=raw for raw 0}, transfer-property=TRIGGERED-ON-CHANGE  # First Word(ASCII) in WPC S/W Ver
          signal ISignal_BCAN_WPC_FD_01_200ms_WPC_SWVerMinor1: start 88, 7 bit, little-endian, init-value=0, base-type=uint8, compu {phys=raw for raw 0}, transfer-property=TRIGGERED-ON-CHANGE  # Second Word(ASCII) in WPC S/W Ver
          signal ISignal_BCAN_WPC_FD_01_200ms_WPC_SWVerMinor2: start 96, 7 bit, little-endian, init-value=0, base-type=uint8, compu {phys=raw for raw 0}, transfer-property=TRIGGERED-ON-CHANGE  # Third Word(ASCII) in WPC S/W Ver
          signal ISignal_BCAN_WPC_FD_01_200ms_WPC_IndSyncVal: start 104, 3 bit, little-endian, init-value=0, base-type=uint8, compu {phys=raw for raw 0}, transfer-property=TRIGGERED-ON-CHANGE
          signal ISignal_BCAN_WPC_FD_01_200ms_USM_CmdWPCIndSta: start 107, 3 bit, little-endian, init-value=2, base-type=uint8, compu {phys=raw for raw 0}, transfer-property=TRIGGERED-ON-CHANGE
          signal ISignal_BCAN_WPC_FD_01_200ms_WPC_ResetOpSta: start 110, 2 bit, little-endian, init-value=0, base-type=uint8, compu {phys=raw for raw 0}, transfer-property=TRIGGERED-ON-CHANGE  # This signal indicates whether the reset operation has been completed or not
          signal ISignal_BCAN_WPC_FD_01_200ms_WPC_FD_01_200ms_E2EReserved: start 120, 8 bit, little-endian, init-value=0, base-type=uint8, compu {phys=0 for raw NaN}
          mapping MsgGr_BCAN_WPC_FD_01_200ms: i-signal-group=MsgGr_E2E_BCAN_WPC_FD_01_200ms, transfer-property=TRIGGERED-ON-CHANGE
      frame CanFrame_BCAN_CLU_01_20ms: id 0x1AA, frame-length=16, can-addressing-mode=STANDARD, can-fd-frame-support=true  # [P] Periodic
        pdu ISignalIPdu_BCAN_CLU_01_20ms: length=16, minimum-delay=0.02, transmission-mode-true-timing=cyclic-timing={time-offset=0.0, time-period=0.1}
          signal ISignal_BCAN_CLU_01_20ms_CLU_DtntOutSta: start 28, 2 bit, little-endian, init-value=0, base-type=uint8, compu {phys=raw for raw 0}, transfer-property=PENDING  # CLU_DetentOutStatus
          signal ISignal_BCAN_CLU_01_20ms_CLU_RhstaLvlSta: start 43, 5 bit, little-endian, init-value=0, base-type=uint8, compu {phys=raw for raw 0}, transfer-property=PENDING  # CLU_RheostatLevelStatus
          signal ISignal_BCAN_CLU_01_20ms_CLU_DisSpdVal_KPH: start 64, 9 bit, little-endian, init-value=0, base-type=uint16, compu {511=Error, phys=raw for raw 0; unit km/h}, unit=km/h, transfer-property=PENDING  # CLU_DisplaySpeedValue_KPH
          signal ISignal_BCAN_CLU_01_20ms_CLU_AutoBrightSta: start 79, 8 bit, little-endian, init-value=0, base-type=uint8, compu {phys=raw for raw 0}, transfer-property=PENDING  # CLU_AutoBrightStatus
      frame CanFrame_BCAN_PDC_FD_03_200ms: id 0x3E2, frame-length=16, can-addressing-mode=STANDARD, can-fd-frame-support=true  # [PE] Periodic and On Event
        pdu ISignalIPdu_BCAN_PDC_FD_03_200ms: length=16, minimum-delay=0.02, transmission-mode-true-timing={cyclic-timing={time-offset=0.0, time-period=0.2}, event-controlled-timing={number-of-repetitions=3, repetition-period=0.04}}
          signal ISignal_BCAN_PDC_FD_03_200ms_Warn_DrvDrSwSta: start 64, 2 bit, little-endian, init-value=0, base-type=uint8, compu {phys=raw for raw 0}, transfer-property=TRIGGERED-ON-CHANGE  # DoorLock_DriverDoorSwitchStatus ##2G## - - C_DrvDrSw,CF_Gway_DrvDrSw,Warn_DrvDrSwSta
          signal ISignal_BCAN_PDC_FD_03_200ms_Warn_AsstDrSwSta: start 66, 2 bit, little-endian, init-value=0, base-type=uint8, compu {phys=raw for raw 0}, transfer-property=TRIGGERED-ON-CHANGE  # Warn_AssistDoorSwitchStatus ##2G## - - C_AstDrSw,CF_Gway_AstDrSw,Warn_AsstDrSwSta
          signal ISignal_BCAN_PDC_FD_03_200ms_Warn_RrLftDrSwSta: start 68, 2 bit, little-endian, init-value=0, base-type=uint8, compu {phys=raw for raw 0}, transfer-property=TRIGGERED-ON-CHANGE  # Warn_RearLeftDoorSwitchStatus ##2G## - - C_RLDrSw,CF_Gway_RLDrSw,Warn_RrLftDrSwSta
          signal ISignal_BCAN_PDC_FD_03_200ms_Warn_RrRtDrSwSta: start 70, 2 bit, little-endian, init-value=0, base-type=uint8, compu {phys=raw for raw 0}, transfer-property=TRIGGERED-ON-CHANGE  # Warn_RearRightDoorSwitchStatus ##2G## - - C_RRDrSw,CF_Gway_RRDrSw,Warn_RrRtDrSwSta
      frame CanFrame_BCAN_BDC_FD_02_200ms: id 0x3D1, frame-length=32, can-addressing-mode=STANDARD, can-fd-frame-support=true  # [PE] Periodic and On Event
        pdu ISignalIPdu_BCAN_BDC_FD_02_200ms: length=32, minimum-delay=0.02, transmission-mode-true-timing={cyclic-timing={time-offset=0.0, time-period=0.2}, event-controlled-timing={number-of-repetitions=3, repetition-period=0.04}}
          signal ISignal_BCAN_BDC_FD_02_200ms_BCM_SmkOptTyp: start 42, 2 bit, little-endian, init-value=0, base-type=uint8, compu {phys=raw for raw 0}, transfer-property=TRIGGERED-ON-CHANGE  # BCM_SmkOptionType ##2G##BCM - BCMmsg17 - C_SMKOption
      frame CanFrame_BCAN_BDC_FD_05_200ms: id 0x3D4, frame-length=32, can-addressing-mode=STANDARD, can-fd-frame-support=true  # [PE] Periodic and On Event
        pdu ISignalIPdu_BCAN_BDC_FD_05_200ms: length=32, minimum-delay=0.02, transmission-mode-true-timing={cyclic-timing={time-offset=0.01, time-period=0.2}, event-controlled-timing={number-of-repetitions=3, repetition-period=0.04}}
          signal ISignal_BCAN_BDC_FD_05_200ms_Lamp_IntTailLmpOnReq: start 62, 2 bit, little-endian, init-value=0, base-type=uint8, compu {phys=raw for raw 0}, transfer-property=TRIGGERED-ON-CHANGE  # Lamp_InternalTailLampOnRequest ##2G##BCM - BCMmsg19 - C_IntTailOn
      frame CanFrame_BCAN_NM_SHVU_CCS_FD: id 0x17FC0065, frame-length=32, can-addressing-mode=EXTENDED, can-fd-frame-support=true
        nm pdu NmPdu_BCAN_NM_SHVU_CCS_FD: length=32
          signal ISignal_BCAN_NM_SHVU_CCS_FD_SNI_SHVU_CCS_FD: start 0, 8 bit, little-endian, init-value=0, base-type=uint8, compu {phys=raw for raw 0}, transfer-property=PENDING  # ASR NM Source Node Identifier
          signal ISignal_BCAN_NM_SHVU_CCS_FD_CBV_RMR_SHVU_CCS_FD: start 8, 1 bit, little-endian, init-value=0, base-type=boolean, compu {phys=raw for raw 0}, transfer-property=PENDING  # ASR NM Control Bit Vector - Repeat Message Request
          signal ISignal_BCAN_NM_SHVU_CCS_FD_CBV_NMCoID_SHVU_CCS_FD: start 9, 2 bit, little-endian, init-value=0, base-type=uint8, compu {phys=raw for raw 0}, transfer-property=PENDING  # ASR NM Control Bit Vector - ASR NM Coordinator ID
          signal ISignal_BCAN_NM_SHVU_CCS_FD_CBV_NMCoSRB_SHVU_CCS_FD: start 11, 1 bit, little-endian, init-value=0, base-type=boolean, compu {phys=raw for raw 0}, transfer-property=PENDING  # ASR NM Control Bit Vector - ASR NM Coordinator Sleep Ready Bit
          signal ISignal_BCAN_NM_SHVU_CCS_FD_CBV_AWB_SHVU_CCS_FD: start 12, 1 bit, little-endian, init-value=0, base-type=boolean, compu {phys=raw for raw 0}, transfer-property=PENDING  # ASR NM Control Bit Vector - Active Wakeup Bit
          signal ISignal_BCAN_NM_SHVU_CCS_FD_CBV_PNIB_SHVU_CCS_FD: start 14, 1 bit, little-endian, init-value=0, base-type=boolean, compu {phys=raw for raw 0}, transfer-property=PENDING  # ASR NM Control Bit Vector - PN Info Bit
          signal ISignal_BCAN_NM_SHVU_CCS_FD_NRR_SHVU_CCS_FD: start 16, 8 bit, little-endian, init-value=0, base-type=uint8, compu {phys=raw for raw 0}, transfer-property=PENDING  # ASR NM Network Request Reason
          signal ISignal_BCAN_NM_SHVU_CCS_FD_NM_State_SHVU_CCS_FD: start 24, 8 bit, little-endian, init-value=0, base-type=uint8, compu {phys=raw for raw 0}, transfer-property=PENDING  # ASR NM State_Current State_Previous State
          signal ISignal_BCAN_NM_SHVU_CCS_FD_PNI_SHVU_CCS_FD: start 32, 32 bit, little-endian, init-value=0, base-type=uint32, compu {phys=raw for raw 0}, transfer-property=PENDING  # ASR NM Partial Networking Information
          signal ISignal_BCAN_NM_SHVU_CCS_FD_PNI_SHVU_CCS_FD_1: start 64, 64 bit, opaque, init-value=8 x 0, compu {phys=raw for raw 0}, implementation-data-type=array8uint8, transfer-property=PENDING  # ASR NM Partial Networking Information
          signal ISignal_BCAN_NM_SHVU_CCS_FD_PNI_SHVU_CCS_FD_2: start 128, 64 bit, opaque, init-value=8 x 0, compu {phys=raw for raw 0}, implementation-data-type=array8uint8, transfer-property=PENDING  # ASR NM Partial Networking Information
          signal ISignal_BCAN_NM_SHVU_CCS_FD_PNI_SHVU_CCS_FD_3: start 192, 64 bit, opaque, init-value=8 x 0, compu {phys=raw for raw 0}, implementation-data-type=array8uint8, transfer-property=PENDING  # ASR NM Partial Networking Information
      frame CanFrame_BCAN_NM_ARS_FD: id 0x17FC008A, frame-length=32, can-addressing-mode=EXTENDED, can-fd-frame-support=true
        nm pdu NmPdu_BCAN_NM_ARS_FD: length=32
          signal ISignal_BCAN_NM_ARS_FD_SNI_ARS_FD: start 0, 8 bit, little-endian, init-value=0, base-type=uint8, compu {phys=raw for raw 0}, transfer-property=PENDING  # ASR NM Source Node Identifier
          signal ISignal_BCAN_NM_ARS_FD_CBV_RMR_ARS_FD: start 8, 1 bit, little-endian, init-value=0, base-type=boolean, compu {phys=raw for raw 0}, transfer-property=PENDING  # ASR NM Control Bit Vector - Repeat Message Request
          signal ISignal_BCAN_NM_ARS_FD_CBV_NMCoID_ARS_FD: start 9, 2 bit, little-endian, init-value=0, base-type=uint8, compu {phys=raw for raw 0}, transfer-property=PENDING  # ASR NM Control Bit Vector - ASR NM Coordinator ID
          signal ISignal_BCAN_NM_ARS_FD_CBV_NMCoSRB_ARS_FD: start 11, 1 bit, little-endian, init-value=0, base-type=boolean, compu {phys=raw for raw 0}, transfer-property=PENDING  # ASR NM Control Bit Vector - ASR NM Coordinator Sleep Ready Bit
          signal ISignal_BCAN_NM_ARS_FD_CBV_AWB_ARS_FD: start 12, 1 bit, little-endian, init-value=0, base-type=boolean, compu {phys=raw for raw 0}, transfer-property=PENDING  # ASR NM Control Bit Vector - Active Wakeup Bit
          signal ISignal_BCAN_NM_ARS_FD_CBV_PNIB_ARS_FD: start 14, 1 bit, little-endian, init-value=0, base-type=boolean, compu {phys=raw for raw 0}, transfer-property=PENDING  # ASR NM Control Bit Vector - PN Info Bit
          signal ISignal_BCAN_NM_ARS_FD_NRR_ARS_FD: start 16, 8 bit, little-endian, init-value=0, base-type=uint8, compu {phys=raw for raw 0}, transfer-property=PENDING  # ASR NM Network Request Reason
          signal ISignal_BCAN_NM_ARS_FD_NM_State_ARS_FD: start 24, 8 bit, little-endian, init-value=0, base-type=uint8, compu {phys=raw for raw 0}, transfer-property=PENDING  # ASR NM State_Current State_Previous State
          signal ISignal_BCAN_NM_ARS_FD_PNI_ARS_FD: start 32, 32 bit, little-endian, init-value=0, base-type=uint32, compu {phys=raw for raw 0}, transfer-property=PENDING  # ASR NM Partial Networking Information
          signal ISignal_BCAN_NM_ARS_FD_PNI_ARS_FD_1: start 64, 64 bit, opaque, init-value=8 x 0, compu {phys=raw for raw 0}, implementation-data-type=array8uint8, transfer-property=PENDING  # ASR NM Partial Networking Information
          signal ISignal_BCAN_NM_ARS_FD_PNI_ARS_FD_2: start 128, 64 bit, opaque, init-value=8 x 0, compu {phys=raw for raw 0}, implementation-data-type=array8uint8, transfer-property=PENDING  # ASR NM Partial Networking Information
          signal ISignal_BCAN_NM_ARS_FD_PNI_ARS_FD_3: start 192, 64 bit, opaque, init-value=8 x 0, compu {phys=raw for raw 0}, implementation-data-type=array8uint8, transfer-property=PENDING  # ASR NM Partial Networking Information
      frame CanFrame_BCAN_NM_WPC_FD: id 0x17FC009E, frame-length=32, can-addressing-mode=EXTENDED, can-fd-frame-support=true
        nm pdu NmPdu_BCAN_NM_WPC_FD: length=32
          signal ISignal_BCAN_NM_WPC_FD_SNI_WPC_FD: start 0, 8 bit, little-endian, init-value=0, base-type=uint8, compu {phys=raw for raw 0}, transfer-property=PENDING  # ASR NM Source Node Identifier
          signal ISignal_BCAN_NM_WPC_FD_CBV_RMR_WPC_FD: start 8, 1 bit, little-endian, init-value=0, base-type=boolean, compu {phys=raw for raw 0}, transfer-property=PENDING  # ASR NM Control Bit Vector - Repeat Message Request
          signal ISignal_BCAN_NM_WPC_FD_CBV_NMCoID_WPC_FD: start 9, 2 bit, little-endian, init-value=0, base-type=uint8, compu {phys=raw for raw 0}, transfer-property=PENDING  # ASR NM Control Bit Vector - ASR NM Coordinator ID
          signal ISignal_BCAN_NM_WPC_FD_CBV_NMCoSRB_WPC_FD: start 11, 1 bit, little-endian, init-value=0, base-type=boolean, compu {phys=raw for raw 0}, transfer-property=PENDING  # ASR NM Control Bit Vector - ASR NM Coordinator Sleep Ready Bit
          signal ISignal_BCAN_NM_WPC_FD_CBV_AWB_WPC_FD: start 12, 1 bit, little-endian, init-value=0, base-type=boolean, compu {phys=raw for raw 0}, transfer-property=PENDING  # ASR NM Control Bit Vector - Active Wakeup Bit
          signal ISignal_BCAN_NM_WPC_FD_CBV_PNIB_WPC_FD: start 14, 1 bit, little-endian, init-value=0, base-type=boolean, compu {phys=raw for raw 0}, transfer-property=PENDING  # ASR NM Control Bit Vector - PN Info Bit
          signal ISignal_BCAN_NM_WPC_FD_NRR_WPC_FD: start 16, 8 bit, little-endian, init-value=0, base-type=uint8, compu {phys=raw for raw 0}, transfer-property=PENDING  # ASR NM Network Request Reason
          signal ISignal_BCAN_NM_WPC_FD_NM_State_WPC_FD: start 24, 8 bit, little-endian, init-value=0, base-type=uint8, compu {phys=raw for raw 0}, transfer-property=PENDING  # ASR NM State_Current State_Previous State
          signal ISignal_BCAN_NM_WPC_FD_PNI_WPC_FD: start 32, 32 bit, little-endian, init-value=0, base-type=uint32, compu {phys=raw for raw 0}, transfer-property=PENDING  # ASR NM Partial Networking Information
          signal ISignal_BCAN_NM_WPC_FD_PNI_WPC_FD_1: start 64, 64 bit, opaque, init-value=8 x 0, compu {phys=raw for raw 0}, implementation-data-type=array8uint8, transfer-property=PENDING  # ASR NM Partial Networking Information
          signal ISignal_BCAN_NM_WPC_FD_PNI_WPC_FD_2: start 128, 64 bit, opaque, init-value=8 x 0, compu {phys=raw for raw 0}, implementation-data-type=array8uint8, transfer-property=PENDING  # ASR NM Partial Networking Information
          signal ISignal_BCAN_NM_WPC_FD_PNI_WPC_FD_3: start 192, 64 bit, opaque, init-value=8 x 0, compu {phys=raw for raw 0}, implementation-data-type=array8uint8, transfer-property=PENDING  # ASR NM Partial Networking Information
      frame CanFrame_BCAN_NM_WPC2_FD: id 0x17FC0095, frame-length=32, can-addressing-mode=EXTENDED, can-fd-frame-support=true
        nm pdu NmPdu_BCAN_NM_WPC2_FD: length=32
          signal ISignal_BCAN_NM_WPC2_FD_SNI_WPC2_FD: start 0, 8 bit, little-endian, init-value=0, base-type=uint8, compu {phys=raw for raw 0}, transfer-property=PENDING  # ASR NM Source Node Identifier
          signal ISignal_BCAN_NM_WPC2_FD_CBV_RMR_WPC2_FD: start 8, 1 bit, little-endian, init-value=0, base-type=boolean, compu {phys=raw for raw 0}, transfer-property=PENDING  # ASR NM Control Bit Vector - Repeat Message Request
          signal ISignal_BCAN_NM_WPC2_FD_CBV_NMCoID_WPC2_FD: start 9, 2 bit, little-endian, init-value=0, base-type=uint8, compu {phys=raw for raw 0}, transfer-property=PENDING  # ASR NM Control Bit Vector - ASR NM Coordinator ID
          signal ISignal_BCAN_NM_WPC2_FD_CBV_NMCoSRB_WPC2_FD: start 11, 1 bit, little-endian, init-value=0, base-type=boolean, compu {phys=raw for raw 0}, transfer-property=PENDING  # ASR NM Control Bit Vector - ASR NM Coordinator Sleep Ready Bit
          signal ISignal_BCAN_NM_WPC2_FD_CBV_AWB_WPC2_FD: start 12, 1 bit, little-endian, init-value=0, base-type=boolean, compu {phys=raw for raw 0}, transfer-property=PENDING  # ASR NM Control Bit Vector - Active Wakeup Bit
          signal ISignal_BCAN_NM_WPC2_FD_CBV_PNIB_WPC2_FD: start 14, 1 bit, little-endian, init-value=0, base-type=boolean, compu {phys=raw for raw 0}, transfer-property=PENDING  # ASR NM Control Bit Vector - PN Info Bit
          signal ISignal_BCAN_NM_WPC2_FD_NRR_WPC2_FD: start 16, 8 bit, little-endian, init-value=0, base-type=uint8, compu {phys=raw for raw 0}, transfer-property=PENDING  # ASR NM Network Request Reason
          signal ISignal_BCAN_NM_WPC2_FD_NM_State_WPC2_FD: start 24, 8 bit, little-endian, init-value=0, base-type=uint8, compu {phys=raw for raw 0}, transfer-property=PENDING  # ASR NM State_Current State_Previous State
          signal ISignal_BCAN_NM_WPC2_FD_PNI_WPC2_FD: start 32, 32 bit, little-endian, init-value=0, base-type=uint32, compu {phys=raw for raw 0}, transfer-property=PENDING  # ASR NM Partial Networking Information
          signal ISignal_BCAN_NM_WPC2_FD_PNI_WPC2_FD_1: start 64, 64 bit, opaque, init-value=8 x 0, compu {phys=raw for raw 0}, implementation-data-type=array8uint8, transfer-property=PENDING  # ASR NM Partial Networking Information
          signal ISignal_BCAN_NM_WPC2_FD_PNI_WPC2_FD_2: start 128, 64 bit, opaque, init-value=8 x 0, compu {phys=raw for raw 0}, implementation-data-type=array8uint8, transfer-property=PENDING  # ASR NM Partial Networking Information
          signal ISignal_BCAN_NM_WPC2_FD_PNI_WPC2_FD_3: start 192, 64 bit, opaque, init-value=8 x 0, compu {phys=raw for raw 0}, implementation-data-type=array8uint8, transfer-property=PENDING  # ASR NM Partial Networking Information
      frame CanFrame_BCAN_NM_SCM_FD: id 0x17FC0087, frame-length=32, can-addressing-mode=EXTENDED, can-fd-frame-support=true
        nm pdu NmPdu_BCAN_NM_SCM_FD: length=32
          signal ISignal_BCAN_NM_SCM_FD_SNI_SCM_FD: start 0, 8 bit, little-endian, init-value=0, base-type=uint8, compu {phys=raw for raw 0}, transfer-property=PENDING  # ASR NM Source Node Identifier
          signal ISignal_BCAN_NM_SCM_FD_CBV_RMR_SCM_FD: start 8, 1 bit, little-endian, init-value=0, base-type=boolean, compu {phys=raw for raw 0}, transfer-property=PENDING  # ASR NM Control Bit Vector - Repeat Message Request
          signal ISignal_BCAN_NM_SCM_FD_CBV_NMCoID_SCM_FD: start 9, 2 bit, little-endian, init-value=0, base-type=uint8, compu {phys=raw for raw 0}, transfer-property=PENDING  # ASR NM Control Bit Vector - ASR NM Coordinator ID
          signal ISignal_BCAN_NM_SCM_FD_CBV_NMCoSRB_SCM_FD: start 11, 1 bit, little-endian, init-value=0, base-type=boolean, compu {phys=raw for raw 0}, transfer-property=PENDING  # ASR NM Control Bit Vector - ASR NM Coordinator Sleep Ready Bit
          signal ISignal_BCAN_NM_SCM_FD_CBV_AWB_SCM_FD: start 12, 1 bit, little-endian, init-value=0, base-type=boolean, compu {phys=raw for raw 0}, transfer-property=PENDING  # ASR NM Control Bit Vector - Active Wakeup Bit
          signal ISignal_BCAN_NM_SCM_FD_CBV_PNIB_SCM_FD: start 14, 1 bit, little-endian, init-value=0, base-type=boolean, compu {phys=raw for raw 0}, transfer-property=PENDING  # ASR NM Control Bit Vector - PN Info Bit
          signal ISignal_BCAN_NM_SCM_FD_NRR_SCM_FD: start 16, 8 bit, little-endian, init-value=0, base-type=uint8, compu {phys=raw for raw 0}, transfer-property=PENDING  # ASR NM Network Request Reason
          signal ISignal_BCAN_NM_SCM_FD_NM_State_SCM_FD: start 24, 8 bit, little-endian, init-value=0, base-type=uint8, compu {phys=raw for raw 0}, transfer-property=PENDING  # ASR NM State_Current State_Previous State
          signal ISignal_BCAN_NM_SCM_FD_PNI_SCM_FD: start 32, 32 bit, little-endian, init-value=0, base-type=uint32, compu {phys=raw for raw 0}, transfer-property=PENDING  # ASR NM Partial Networking Information
          signal ISignal_BCAN_NM_SCM_FD_PNI_SCM_FD_1: start 64, 64 bit, opaque, init-value=8 x 0, compu {phys=raw for raw 0}, implementation-data-type=array8uint8, transfer-property=PENDING  # ASR NM Partial Networking Information
          signal ISignal_BCAN_NM_SCM_FD_PNI_SCM_FD_2: start 128, 64 bit, opaque, init-value=8 x 0, compu {phys=raw for raw 0}, implementation-data-type=array8uint8, transfer-property=PENDING  # ASR NM Partial Networking Information
          signal ISignal_BCAN_NM_SCM_FD_PNI_SCM_FD_3: start 192, 64 bit, opaque, init-value=8 x 0, compu {phys=raw for raw 0}, implementation-data-type=array8uint8, transfer-property=PENDING  # ASR NM Partial Networking Information
      frame CanFrame_BCAN_NM_SHVU_FRNT_FD: id 0x17FC00AA, frame-length=32, can-addressing-mode=EXTENDED, can-fd-frame-support=true
        nm pdu NmPdu_BCAN_NM_SHVU_FRNT_FD: length=32
          signal ISignal_BCAN_NM_SHVU_FRNT_FD_SNI_SHVU_FRNT_FD: start 0, 8 bit, little-endian, init-value=0, base-type=uint8, compu {phys=raw for raw 0}, transfer-property=PENDING  # ASR NM Source Node Identifier
          signal ISignal_BCAN_NM_SHVU_FRNT_FD_CBV_RMR_SHVU_FRNT_FD: start 8, 1 bit, little-endian, init-value=0, base-type=boolean, compu {phys=raw for raw 0}, transfer-property=PENDING  # ASR NM Control Bit Vector - Repeat Message Request
          signal ISignal_BCAN_NM_SHVU_FRNT_FD_CBV_NMCoID_SHVU_FRNT_FD: start 9, 2 bit, little-endian, init-value=0, base-type=uint8, compu {phys=raw for raw 0}, transfer-property=PENDING  # ASR NM Control Bit Vector - ASR NM Coordinator ID
          signal ISignal_BCAN_NM_SHVU_FRNT_FD_CBV_NMCoSRB_SHVU_FRNT_FD: start 11, 1 bit, little-endian, init-value=0, base-type=boolean, compu {phys=raw for raw 0}, transfer-property=PENDING  # ASR NM Control Bit Vector - ASR NM Coordinator Sleep Ready Bit
          signal ISignal_BCAN_NM_SHVU_FRNT_FD_CBV_AWB_SHVU_FRNT_FD: start 12, 1 bit, little-endian, init-value=0, base-type=boolean, compu {phys=raw for raw 0}, transfer-property=PENDING  # ASR NM Control Bit Vector - Active Wakeup Bit
          signal ISignal_BCAN_NM_SHVU_FRNT_FD_CBV_PNIB_SHVU_FRNT_FD: start 14, 1 bit, little-endian, init-value=0, base-type=boolean, compu {phys=raw for raw 0}, transfer-property=PENDING  # ASR NM Control Bit Vector - PN Info Bit
          signal ISignal_BCAN_NM_SHVU_FRNT_FD_NRR_SHVU_FRNT_FD: start 16, 8 bit, little-endian, init-value=0, base-type=uint8, compu {phys=raw for raw 0}, transfer-property=PENDING  # ASR NM Network Request Reason
          signal ISignal_BCAN_NM_SHVU_FRNT_FD_NM_State_SHVU_FRNT_FD: start 24, 8 bit, little-endian, init-value=0, base-type=uint8, compu {phys=raw for raw 0}, transfer-property=PENDING  # ASR NM State_Current State_Previous State
          signal ISignal_BCAN_NM_SHVU_FRNT_FD_PNI_SHVU_FRNT_FD: start 32, 32 bit, little-endian, init-value=0, base-type=uint32, compu {phys=raw for raw 0}, transfer-property=PENDING  # ASR NM Partial Networking Information
          signal ISignal_BCAN_NM_SHVU_FRNT_FD_PNI_SHVU_FRNT_FD_1: start 64, 64 bit, opaque, init-value=8 x 0, compu {phys=raw for raw 0}, implementation-data-type=array8uint8, transfer-property=PENDING  # ASR NM Partial Networking Information
          signal ISignal_BCAN_NM_SHVU_FRNT_FD_PNI_SHVU_FRNT_FD_2: start 128, 64 bit, opaque, init-value=8 x 0, compu {phys=raw for raw 0}, implementation-data-type=array8uint8, transfer-property=PENDING  # ASR NM Partial Networking Information
          signal ISignal_BCAN_NM_SHVU_FRNT_FD_PNI_SHVU_FRNT_FD_3: start 192, 64 bit, opaque, init-value=8 x 0, compu {phys=raw for raw 0}, implementation-data-type=array8uint8, transfer-property=PENDING  # ASR NM Partial Networking Information
      frame CanFrame_BCAN_NM_FLLR_FD: id 0x17FC003E, frame-length=32, can-addressing-mode=EXTENDED, can-fd-frame-support=true
        nm pdu NmPdu_BCAN_NM_FLLR_FD: length=32
          signal ISignal_BCAN_NM_FLLR_FD_SNI_FLLR_FD: start 0, 8 bit, little-endian, init-value=0, base-type=uint8, compu {phys=raw for raw 0}, transfer-property=PENDING  # ASR NM Source Node Identifier
          signal ISignal_BCAN_NM_FLLR_FD_CBV_RMR_FLLR_FD: start 8, 1 bit, little-endian, init-value=0, base-type=boolean, compu {phys=raw for raw 0}, transfer-property=PENDING  # ASR NM Control Bit Vector - Repeat Message Request
          signal ISignal_BCAN_NM_FLLR_FD_CBV_NMCoID_FLLR_FD: start 9, 2 bit, little-endian, init-value=0, base-type=uint8, compu {phys=raw for raw 0}, transfer-property=PENDING  # ASR NM Control Bit Vector - ASR NM Coordinator ID
          signal ISignal_BCAN_NM_FLLR_FD_CBV_NMCoSRB_FLLR_FD: start 11, 1 bit, little-endian, init-value=0, base-type=boolean, compu {phys=raw for raw 0}, transfer-property=PENDING  # ASR NM Control Bit Vector - ASR NM Coordinator Sleep Ready Bit
          signal ISignal_BCAN_NM_FLLR_FD_CBV_AWB_FLLR_FD: start 12, 1 bit, little-endian, init-value=0, base-type=boolean, compu {phys=raw for raw 0}, transfer-property=PENDING  # ASR NM Control Bit Vector - Active Wakeup Bit
          signal ISignal_BCAN_NM_FLLR_FD_CBV_PNIB_FLLR_FD: start 14, 1 bit, little-endian, init-value=0, base-type=boolean, compu {phys=raw for raw 0}, transfer-property=PENDING  # ASR NM Control Bit Vector - PN Info Bit
          signal ISignal_BCAN_NM_FLLR_FD_NRR_FLLR_FD: start 16, 8 bit, little-endian, init-value=0, base-type=uint8, compu {phys=raw for raw 0}, transfer-property=PENDING  # ASR NM Network Request Reason
          signal ISignal_BCAN_NM_FLLR_FD_NM_State_FLLR_FD: start 24, 8 bit, little-endian, init-value=0, base-type=uint8, compu {phys=raw for raw 0}, transfer-property=PENDING  # ASR NM State_Current State_Previous State
          signal ISignal_BCAN_NM_FLLR_FD_PNI_FLLR_FD: start 32, 32 bit, little-endian, init-value=0, base-type=uint32, compu {phys=raw for raw 0}, transfer-property=PENDING  # ASR NM Partial Networking Information
          signal ISignal_BCAN_NM_FLLR_FD_PNI_FLLR_FD_1: start 64, 64 bit, opaque, init-value=8 x 0, compu {phys=raw for raw 0}, implementation-data-type=array8uint8, transfer-property=PENDING  # ASR NM Partial Networking Information
          signal ISignal_BCAN_NM_FLLR_FD_PNI_FLLR_FD_2: start 128, 64 bit, opaque, init-value=8 x 0, compu {phys=raw for raw 0}, implementation-data-type=array8uint8, transfer-property=PENDING  # ASR NM Partial Networking Information
          signal ISignal_BCAN_NM_FLLR_FD_PNI_FLLR_FD_3: start 192, 64 bit, opaque, init-value=8 x 0, compu {phys=raw for raw 0}, implementation-data-type=array8uint8, transfer-property=PENDING  # ASR NM Partial Networking Information
      frame CanFrame_BCAN_NM_GW_SAU_DRV_FD: id 0x17FC00D9, frame-length=32, can-addressing-mode=EXTENDED, can-fd-frame-support=true
        nm pdu NmPdu_BCAN_NM_GW_SAU_DRV_FD: length=32
          signal ISignal_BCAN_NM_GW_SAU_DRV_FD_SNI_GW_SAU_DRV_FD: start 0, 8 bit, little-endian, init-value=0, base-type=uint8, compu {phys=raw for raw 0}, transfer-property=PENDING  # ASR NM Source Node Identifier
          signal ISignal_BCAN_NM_GW_SAU_DRV_FD_CBV_RMR_GW_SAU_DRV_FD: start 8, 1 bit, little-endian, init-value=0, base-type=boolean, compu {phys=raw for raw 0}, transfer-property=PENDING  # ASR NM Control Bit Vector - Repeat Message Request
          signal ISignal_BCAN_NM_GW_SAU_DRV_FD_CBV_NMCoID_GW_SAU_DRV_FD: start 9, 2 bit, little-endian, init-value=0, base-type=uint8, compu {phys=raw for raw 0}, transfer-property=PENDING  # ASR NM Control Bit Vector - ASR NM Coordinator ID
          signal ISignal_BCAN_NM_GW_SAU_DRV_FD_CBV_NMCoSRB_GW_SAU_DRV_FD: start 11, 1 bit, little-endian, init-value=0, base-type=boolean, compu {phys=raw for raw 0}, transfer-property=PENDING  # ASR NM Control Bit Vector - ASR NM Coordinator Sleep Ready Bit
          signal ISignal_BCAN_NM_GW_SAU_DRV_FD_CBV_AWB_GW_SAU_DRV_FD: start 12, 1 bit, little-endian, init-value=0, base-type=boolean, compu {phys=raw for raw 0}, transfer-property=PENDING  # ASR NM Control Bit Vector - Active Wakeup Bit
          signal ISignal_BCAN_NM_GW_SAU_DRV_FD_CBV_PNIB_GW_SAU_DRV_FD: start 14, 1 bit, little-endian, init-value=0, base-type=boolean, compu {phys=raw for raw 0}, transfer-property=PENDING  # ASR NM Control Bit Vector - PN Info Bit
          signal ISignal_BCAN_NM_GW_SAU_DRV_FD_NRR_GW_SAU_DRV_FD: start 16, 8 bit, little-endian, init-value=0, base-type=uint8, compu {phys=raw for raw 0}, transfer-property=PENDING  # ASR NM Network Request Reason
          signal ISignal_BCAN_NM_GW_SAU_DRV_FD_NM_State_GW_SAU_DRV_FD: start 24, 8 bit, little-endian, init-value=0, base-type=uint8, compu {phys=raw for raw 0}, transfer-property=PENDING  # ASR NM State_Current State_Previous State
          signal ISignal_BCAN_NM_GW_SAU_DRV_FD_PNI_GW_SAU_DRV_FD: start 32, 32 bit, little-endian, init-value=0, base-type=uint32, compu {phys=raw for raw 0}, transfer-property=PENDING  # ASR NM Partial Networking Information
          signal ISignal_BCAN_NM_GW_SAU_DRV_FD_PNI_GW_SAU_DRV_FD_1: start 64, 64 bit, opaque, init-value=8 x 0, compu {phys=raw for raw 0}, implementation-data-type=array8uint8, transfer-property=PENDING  # ASR NM Partial Networking Information
          signal ISignal_BCAN_NM_GW_SAU_DRV_FD_PNI_GW_SAU_DRV_FD_2: start 128, 64 bit, opaque, init-value=8 x 0, compu {phys=raw for raw 0}, implementation-data-type=array8uint8, transfer-property=PENDING  # ASR NM Partial Networking Information
          signal ISignal_BCAN_NM_GW_SAU_DRV_FD_PNI_GW_SAU_DRV_FD_3: start 192, 64 bit, opaque, init-value=8 x 0, compu {phys=raw for raw 0}, implementation-data-type=array8uint8, transfer-property=PENDING  # ASR NM Partial Networking Information
      frame CanFrame_BCAN_NM_ATS_FD: id 0x17FC00D0, frame-length=32, can-addressing-mode=EXTENDED, can-fd-frame-support=true
        nm pdu NmPdu_BCAN_NM_ATS_FD: length=32
          signal ISignal_BCAN_NM_ATS_FD_SNI_ATS_FD: start 0, 8 bit, little-endian, init-value=0, base-type=uint8, compu {phys=raw for raw 0}, transfer-property=PENDING  # ASR NM Source Node Identifier
          signal ISignal_BCAN_NM_ATS_FD_CBV_RMR_ATS_FD: start 8, 1 bit, little-endian, init-value=0, base-type=boolean, compu {phys=raw for raw 0}, transfer-property=PENDING  # ASR NM Control Bit Vector - Repeat Message Request
          signal ISignal_BCAN_NM_ATS_FD_CBV_NMCoID_ATS_FD: start 9, 2 bit, little-endian, init-value=0, base-type=uint8, compu {phys=raw for raw 0}, transfer-property=PENDING  # ASR NM Control Bit Vector - ASR NM Coordinator ID
          signal ISignal_BCAN_NM_ATS_FD_CBV_NMCoSRB_ATS_FD: start 11, 1 bit, little-endian, init-value=0, base-type=boolean, compu {phys=raw for raw 0}, transfer-property=PENDING  # ASR NM Control Bit Vector - ASR NM Coordinator Sleep Ready Bit
          signal ISignal_BCAN_NM_ATS_FD_CBV_AWB_ATS_FD: start 12, 1 bit, little-endian, init-value=0, base-type=boolean, compu {phys=raw for raw 0}, transfer-property=PENDING  # ASR NM Control Bit Vector - Active Wakeup Bit
          signal ISignal_BCAN_NM_ATS_FD_CBV_PNIB_ATS_FD: start 14, 1 bit, little-endian, init-value=0, base-type=boolean, compu {phys=raw for raw 0}, transfer-property=PENDING  # ASR NM Control Bit Vector - PN Info Bit
          signal ISignal_BCAN_NM_ATS_FD_NRR_ATS_FD: start 16, 8 bit, little-endian, init-value=0, base-type=uint8, compu {phys=raw for raw 0}, transfer-property=PENDING  # ASR NM Network Request Reason
          signal ISignal_BCAN_NM_ATS_FD_NM_State_ATS_FD: start 24, 8 bit, little-endian, init-value=0, base-type=uint8, compu {phys=raw for raw 0}, transfer-property=PENDING  # ASR NM State_Current State_Previous State
          signal ISignal_BCAN_NM_ATS_FD_PNI_ATS_FD: start 32, 32 bit, little-endian, init-value=0, base-type=uint32, compu {phys=raw for raw 0}, transfer-property=PENDING  # ASR NM Partial Networking Information
          signal ISignal_BCAN_NM_ATS_FD_PNI_ATS_FD_1: start 64, 64 bit, opaque, init-value=8 x 0, compu {phys=raw for raw 0}, implementation-data-type=array8uint8, transfer-property=PENDING  # ASR NM Partial Networking Information
          signal ISignal_BCAN_NM_ATS_FD_PNI_ATS_FD_2: start 128, 64 bit, opaque, init-value=8 x 0, compu {phys=raw for raw 0}, implementation-data-type=array8uint8, transfer-property=PENDING  # ASR NM Partial Networking Information
          signal ISignal_BCAN_NM_ATS_FD_PNI_ATS_FD_3: start 192, 64 bit, opaque, init-value=8 x 0, compu {phys=raw for raw 0}, implementation-data-type=array8uint8, transfer-property=PENDING  # ASR NM Partial Networking Information
      frame CanFrame_BCAN_NM_PSB_FD: id 0x17FC00C1, frame-length=32, can-addressing-mode=EXTENDED, can-fd-frame-support=true
        nm pdu NmPdu_BCAN_NM_PSB_FD: length=32
          signal ISignal_BCAN_NM_PSB_FD_SNI_PSB_FD: start 0, 8 bit, little-endian, init-value=0, base-type=uint8, compu {phys=raw for raw 0}, transfer-property=PENDING  # ASR NM Source Node Identifier
          signal ISignal_BCAN_NM_PSB_FD_CBV_RMR_PSB_FD: start 8, 1 bit, little-endian, init-value=0, base-type=boolean, compu {phys=raw for raw 0}, transfer-property=PENDING  # ASR NM Control Bit Vector - Repeat Message Request
          signal ISignal_BCAN_NM_PSB_FD_CBV_NMCoID_PSB_FD: start 9, 2 bit, little-endian, init-value=0, base-type=uint8, compu {phys=raw for raw 0}, transfer-property=PENDING  # ASR NM Control Bit Vector - ASR NM Coordinator ID
          signal ISignal_BCAN_NM_PSB_FD_CBV_NMCoSRB_PSB_FD: start 11, 1 bit, little-endian, init-value=0, base-type=boolean, compu {phys=raw for raw 0}, transfer-property=PENDING  # ASR NM Control Bit Vector - ASR NM Coordinator Sleep Ready Bit
          signal ISignal_BCAN_NM_PSB_FD_CBV_AWB_PSB_FD: start 12, 1 bit, little-endian, init-value=0, base-type=boolean, compu {phys=raw for raw 0}, transfer-property=PENDING  # ASR NM Control Bit Vector - Active Wakeup Bit
          signal ISignal_BCAN_NM_PSB_FD_CBV_PNIB_PSB_FD: start 14, 1 bit, little-endian, init-value=0, base-type=boolean, compu {phys=raw for raw 0}, transfer-property=PENDING  # ASR NM Control Bit Vector - PN Info Bit
          signal ISignal_BCAN_NM_PSB_FD_NRR_PSB_FD: start 16, 8 bit, little-endian, init-value=0, base-type=uint8, compu {phys=raw for raw 0}, transfer-property=PENDING  # ASR NM Network Request Reason
          signal ISignal_BCAN_NM_PSB_FD_NM_State_PSB_FD: start 24, 8 bit, little-endian, init-value=0, base-type=uint8, compu {phys=raw for raw 0}, transfer-property=PENDING  # ASR NM State_Current State_Previous State
          signal ISignal_BCAN_NM_PSB_FD_PNI_PSB_FD: start 32, 32 bit, little-endian, init-value=0, base-type=uint32, compu {phys=raw for raw 0}, transfer-property=PENDING  # ASR NM Partial Networking Information
          signal ISignal_BCAN_NM_PSB_FD_PNI_PSB_FD_1: start 64, 64 bit, opaque, init-value=8 x 0, compu {phys=raw for raw 0}, implementation-data-type=array8uint8, transfer-property=PENDING  # ASR NM Partial Networking Information
          signal ISignal_BCAN_NM_PSB_FD_PNI_PSB_FD_2: start 128, 64 bit, opaque, init-value=8 x 0, compu {phys=raw for raw 0}, implementation-data-type=array8uint8, transfer-property=PENDING  # ASR NM Partial Networking Information
          signal ISignal_BCAN_NM_PSB_FD_PNI_PSB_FD_3: start 192, 64 bit, opaque, init-value=8 x 0, compu {phys=raw for raw 0}, implementation-data-type=array8uint8, transfer-property=PENDING  # ASR NM Partial Networking Information
      frame CanFrame_BCAN_NM_GW_PSU_RR_FD: id 0x17FC009D, frame-length=32, can-addressing-mode=EXTENDED, can-fd-frame-support=true
        nm pdu NmPdu_BCAN_NM_GW_PSU_RR_FD: length=32
          signal ISignal_BCAN_NM_GW_PSU_RR_FD_SNI_GW_PSU_RR_FD: start 0, 8 bit, little-endian, init-value=0, base-type=uint8, compu {phys=raw for raw 0}, transfer-property=PENDING  # ASR NM Source Node Identifier
          signal ISignal_BCAN_NM_GW_PSU_RR_FD_CBV_RMR_GW_PSU_RR_FD: start 8, 1 bit, little-endian, init-value=0, base-type=boolean, compu {phys=raw for raw 0}, transfer-property=PENDING  # ASR NM Control Bit Vector - Repeat Message Request
          signal ISignal_BCAN_NM_GW_PSU_RR_FD_CBV_NMCoID_GW_PSU_RR_FD: start 9, 2 bit, little-endian, init-value=0, base-type=uint8, compu {phys=raw for raw 0}, transfer-property=PENDING  # ASR NM Control Bit Vector - ASR NM Coordinator ID
          signal ISignal_BCAN_NM_GW_PSU_RR_FD_CBV_NMCoSRB_GW_PSU_RR_FD: start 11, 1 bit, little-endian, init-value=0, base-type=boolean, compu {phys=raw for raw 0}, transfer-property=PENDING  # ASR NM Control Bit Vector - ASR NM Coordinator Sleep Ready Bit
          signal ISignal_BCAN_NM_GW_PSU_RR_FD_CBV_AWB_GW_PSU_RR_FD: start 12, 1 bit, little-endian, init-value=0, base-type=boolean, compu {phys=raw for raw 0}, transfer-property=PENDING  # ASR NM Control Bit Vector - Active Wakeup Bit
          signal ISignal_BCAN_NM_GW_PSU_RR_FD_CBV_PNIB_GW_PSU_RR_FD: start 14, 1 bit, little-endian, init-value=0, base-type=boolean, compu {phys=raw for raw 0}, transfer-property=PENDING  # ASR NM Control Bit Vector - PN Info Bit
          signal ISignal_BCAN_NM_GW_PSU_RR_FD_NRR_GW_PSU_RR_FD: start 16, 8 bit, little-endian, init-value=0, base-type=uint8, compu {phys=raw for raw 0}, transfer-property=PENDING  # ASR NM Network Request Reason
          signal ISignal_BCAN_NM_GW_PSU_RR_FD_NM_State_GW_PSU_RR_FD: start 24, 8 bit, little-endian, init-value=0, base-type=uint8, compu {phys=raw for raw 0}, transfer-property=PENDING  # ASR NM State_Current State_Previous State
          signal ISignal_BCAN_NM_GW_PSU_RR_FD_PNI_GW_PSU_RR_FD: start 32, 32 bit, little-endian, init-value=0, base-type=uint32, compu {phys=raw for raw 0}, transfer-property=PENDING  # ASR NM Partial Networking Information
          signal ISignal_BCAN_NM_GW_PSU_RR_FD_PNI_GW_PSU_RR_FD_1: start 64, 64 bit, opaque, init-value=8 x 0, compu {phys=raw for raw 0}, implementation-data-type=array8uint8, transfer-property=PENDING  # ASR NM Partial Networking Information
          signal ISignal_BCAN_NM_GW_PSU_RR_FD_PNI_GW_PSU_RR_FD_2: start 128, 64 bit, opaque, init-value=8 x 0, compu {phys=raw for raw 0}, implementation-data-type=array8uint8, transfer-property=PENDING  # ASR NM Partial Networking Information
          signal ISignal_BCAN_NM_GW_PSU_RR_FD_PNI_GW_PSU_RR_FD_3: start 192, 64 bit, opaque, init-value=8 x 0, compu {phys=raw for raw 0}, implementation-data-type=array8uint8, transfer-property=PENDING  # ASR NM Partial Networking Information
      frame CanFrame_BCAN_NM_SHVU_RL_FD: id 0x17FC00B4, frame-length=32, can-addressing-mode=EXTENDED, can-fd-frame-support=true
        nm pdu NmPdu_BCAN_NM_SHVU_RL_FD: length=32
          signal ISignal_BCAN_NM_SHVU_RL_FD_SNI_SHVU_RL_FD: start 0, 8 bit, little-endian, init-value=0, base-type=uint8, compu {phys=raw for raw 0}, transfer-property=PENDING  # ASR NM Source Node Identifier
          signal ISignal_BCAN_NM_SHVU_RL_FD_CBV_RMR_SHVU_RL_FD: start 8, 1 bit, little-endian, init-value=0, base-type=boolean, compu {phys=raw for raw 0}, transfer-property=PENDING  # ASR NM Control Bit Vector - Repeat Message Request
          signal ISignal_BCAN_NM_SHVU_RL_FD_CBV_NMCoID_SHVU_RL_FD: start 9, 2 bit, little-endian, init-value=0, base-type=uint8, compu {phys=raw for raw 0}, transfer-property=PENDING  # ASR NM Control Bit Vector - ASR NM Coordinator ID
          signal ISignal_BCAN_NM_SHVU_RL_FD_CBV_NMCoSRB_SHVU_RL_FD: start 11, 1 bit, little-endian, init-value=0, base-type=boolean, compu {phys=raw for raw 0}, transfer-property=PENDING  # ASR NM Control Bit Vector - ASR NM Coordinator Sleep Ready Bit
          signal ISignal_BCAN_NM_SHVU_RL_FD_CBV_AWB_SHVU_RL_FD: start 12, 1 bit, little-endian, init-value=0, base-type=boolean, compu {phys=raw for raw 0}, transfer-property=PENDING  # ASR NM Control Bit Vector - Active Wakeup Bit
          signal ISignal_BCAN_NM_SHVU_RL_FD_CBV_PNIB_SHVU_RL_FD: start 14, 1 bit, little-endian, init-value=0, base-type=boolean, compu {phys=raw for raw 0}, transfer-property=PENDING  # ASR NM Control Bit Vector - PN Info Bit
          signal ISignal_BCAN_NM_SHVU_RL_FD_NRR_SHVU_RL_FD: start 16, 8 bit, little-endian, init-value=0, base-type=uint8, compu {phys=raw for raw 0}, transfer-property=PENDING  # ASR NM Network Request Reason
          signal ISignal_BCAN_NM_SHVU_RL_FD_NM_State_SHVU_RL_FD: start 24, 8 bit, little-endian, init-value=0, base-type=uint8, compu {phys=raw for raw 0}, transfer-property=PENDING  # ASR NM State_Current State_Previous State
          signal ISignal_BCAN_NM_SHVU_RL_FD_PNI_SHVU_RL_FD: start 32, 32 bit, little-endian, init-value=0, base-type=uint32, compu {phys=raw for raw 0}, transfer-property=PENDING  # ASR NM Partial Networking Information
          signal ISignal_BCAN_NM_SHVU_RL_FD_PNI_SHVU_RL_FD_1: start 64, 64 bit, opaque, init-value=8 x 0, compu {phys=raw for raw 0}, implementation-data-type=array8uint8, transfer-property=PENDING  # ASR NM Partial Networking Information
          signal ISignal_BCAN_NM_SHVU_RL_FD_PNI_SHVU_RL_FD_2: start 128, 64 bit, opaque, init-value=8 x 0, compu {phys=raw for raw 0}, implementation-data-type=array8uint8, transfer-property=PENDING  # ASR NM Partial Networking Information
          signal ISignal_BCAN_NM_SHVU_RL_FD_PNI_SHVU_RL_FD_3: start 192, 64 bit, opaque, init-value=8 x 0, compu {phys=raw for raw 0}, implementation-data-type=array8uint8, transfer-property=PENDING  # ASR NM Partial Networking Information
      frame CanFrame_BCAN_NM_RWPC_FD: id 0x17FC009F, frame-length=32, can-addressing-mode=EXTENDED, can-fd-frame-support=true
        nm pdu NmPdu_BCAN_NM_RWPC_FD: length=32
          signal ISignal_BCAN_NM_RWPC_FD_SNI_RWPC_FD: start 0, 8 bit, little-endian, init-value=0, base-type=uint8, compu {phys=raw for raw 0}, transfer-property=PENDING  # ASR NM Source Node Identifier
          signal ISignal_BCAN_NM_RWPC_FD_CBV_RMR_RWPC_FD: start 8, 1 bit, little-endian, init-value=0, base-type=boolean, compu {phys=raw for raw 0}, transfer-property=PENDING  # ASR NM Control Bit Vector - Repeat Message Request
          signal ISignal_BCAN_NM_RWPC_FD_CBV_NMCoID_RWPC_FD: start 9, 2 bit, little-endian, init-value=0, base-type=uint8, compu {phys=raw for raw 0}, transfer-property=PENDING  # ASR NM Control Bit Vector - ASR NM Coordinator ID
          signal ISignal_BCAN_NM_RWPC_FD_CBV_NMCoSRB_RWPC_FD: start 11, 1 bit, little-endian, init-value=0, base-type=boolean, compu {phys=raw for raw 0}, transfer-property=PENDING  # ASR NM Control Bit Vector - ASR NM Coordinator Sleep Ready Bit
          signal ISignal_BCAN_NM_RWPC_FD_CBV_AWB_RWPC_FD: start 12, 1 bit, little-endian, init-value=0, base-type=boolean, compu {phys=raw for raw 0}, transfer-property=PENDING  # ASR NM Control Bit Vector - Active Wakeup Bit
          signal ISignal_BCAN_NM_RWPC_FD_CBV_PNIB_RWPC_FD: start 14, 1 bit, little-endian, init-value=0, base-type=boolean, compu {phys=raw for raw 0}, transfer-property=PENDING  # ASR NM Control Bit Vector - PN Info Bit
          signal ISignal_BCAN_NM_RWPC_FD_NRR_RWPC_FD: start 16, 8 bit, little-endian, init-value=0, base-type=uint8, compu {phys=raw for raw 0}, transfer-property=PENDING  # ASR NM Network Request Reason
          signal ISignal_BCAN_NM_RWPC_FD_NM_State_RWPC_FD: start 24, 8 bit, little-endian, init-value=0, base-type=uint8, compu {phys=raw for raw 0}, transfer-property=PENDING  # ASR NM State_Current State_Previous State
          signal ISignal_BCAN_NM_RWPC_FD_PNI_RWPC_FD: start 32, 32 bit, little-endian, init-value=0, base-type=uint32, compu {phys=raw for raw 0}, transfer-property=PENDING  # ASR NM Partial Networking Information
          signal ISignal_BCAN_NM_RWPC_FD_PNI_RWPC_FD_1: start 64, 64 bit, opaque, init-value=8 x 0, compu {phys=raw for raw 0}, implementation-data-type=array8uint8, transfer-property=PENDING  # ASR NM Partial Networking Information
          signal ISignal_BCAN_NM_RWPC_FD_PNI_RWPC_FD_2: start 128, 64 bit, opaque, init-value=8 x 0, compu {phys=raw for raw 0}, implementation-data-type=array8uint8, transfer-property=PENDING  # ASR NM Partial Networking Information
          signal ISignal_BCAN_NM_RWPC_FD_PNI_RWPC_FD_3: start 192, 64 bit, opaque, init-value=8 x 0, compu {phys=raw for raw 0}, implementation-data-type=array8uint8, transfer-property=PENDING  # ASR NM Partial Networking Information
      frame CanFrame_BCAN_NM_CGW_CCU: id 0x17FC0070, frame-length=32, can-addressing-mode=EXTENDED, can-fd-frame-support=true
        nm pdu NmPdu_BCAN_NM_CGW_CCU: length=32
          signal ISignal_BCAN_NM_CGW_CCU_SNI_CGW_CCU: start 0, 8 bit, little-endian, init-value=0, base-type=uint8, compu {phys=raw for raw 0}, transfer-property=PENDING  # ASR NM Source Node Identifier
          signal ISignal_BCAN_NM_CGW_CCU_CBV_RMR_CGW_CCU: start 8, 1 bit, little-endian, init-value=0, base-type=boolean, compu {phys=raw for raw 0}, transfer-property=PENDING  # ASR NM Control Bit Vector - Repeat Message Request
          signal ISignal_BCAN_NM_CGW_CCU_CBV_NMCoID_CGW_CCU: start 9, 2 bit, little-endian, init-value=0, base-type=uint8, compu {phys=raw for raw 0}, transfer-property=PENDING  # ASR NM Control Bit Vector - ASR NM Coordinator ID
          signal ISignal_BCAN_NM_CGW_CCU_CBV_NMCoSRB_CGW_CCU: start 11, 1 bit, little-endian, init-value=0, base-type=boolean, compu {phys=raw for raw 0}, transfer-property=PENDING  # ASR NM Control Bit Vector - ASR NM Coordinator Sleep Ready Bit
          signal ISignal_BCAN_NM_CGW_CCU_CBV_AWB_CGW_CCU: start 12, 1 bit, little-endian, init-value=0, base-type=boolean, compu {phys=raw for raw 0}, transfer-property=PENDING  # ASR NM Control Bit Vector - Active Wakeup Bit
          signal ISignal_BCAN_NM_CGW_CCU_CBV_PNIB_CGW_CCU: start 14, 1 bit, little-endian, init-value=0, base-type=boolean, compu {phys=raw for raw 0}, transfer-property=PENDING  # ASR NM Control Bit Vector - PN Info Bit
          signal ISignal_BCAN_NM_CGW_CCU_NRR_CGW_CCU: start 16, 8 bit, little-endian, init-value=0, base-type=uint8, compu {phys=raw for raw 0}, transfer-property=PENDING  # ASR NM Network Request Reason
          signal ISignal_BCAN_NM_CGW_CCU_NM_State_CGW_CCU: start 24, 8 bit, little-endian, init-value=0, base-type=uint8, compu {phys=raw for raw 0}, transfer-property=PENDING  # ASR NM State_Current State_Previous State
          signal ISignal_BCAN_NM_CGW_CCU_PNI_CGW_CCU: start 32, 32 bit, little-endian, init-value=0, base-type=uint32, compu {phys=raw for raw 0}, transfer-property=PENDING  # ASR NM Partial Networking Information
          signal ISignal_BCAN_NM_CGW_CCU_PNI_CGW_CCU_1: start 64, 64 bit, opaque, init-value=8 x 0, compu {phys=raw for raw 0}, implementation-data-type=array8uint8, transfer-property=PENDING  # ASR NM Partial Networking Information
          signal ISignal_BCAN_NM_CGW_CCU_PNI_CGW_CCU_2: start 128, 64 bit, opaque, init-value=8 x 0, compu {phys=raw for raw 0}, implementation-data-type=array8uint8, transfer-property=PENDING  # ASR NM Partial Networking Information
          signal ISignal_BCAN_NM_CGW_CCU_PNI_CGW_CCU_3: start 192, 64 bit, opaque, init-value=8 x 0, compu {phys=raw for raw 0}, implementation-data-type=array8uint8, transfer-property=PENDING  # ASR NM Partial Networking Information
      frame CanFrame_BCAN_NM_OHCL_FD: id 0x17FC00D4, frame-length=32, can-addressing-mode=EXTENDED, can-fd-frame-support=true
        nm pdu NmPdu_BCAN_NM_OHCL_FD: length=32
          signal ISignal_BCAN_NM_OHCL_FD_SNI_OHCL_FD: start 0, 8 bit, little-endian, init-value=0, base-type=uint8, compu {phys=raw for raw 0}, transfer-property=PENDING  # ASR NM Source Node Identifier
          signal ISignal_BCAN_NM_OHCL_FD_CBV_RMR_OHCL_FD: start 8, 1 bit, little-endian, init-value=0, base-type=boolean, compu {phys=raw for raw 0}, transfer-property=PENDING  # ASR NM Control Bit Vector - Repeat Message Request
          signal ISignal_BCAN_NM_OHCL_FD_CBV_NMCoID_OHCL_FD: start 9, 2 bit, little-endian, init-value=0, base-type=uint8, compu {phys=raw for raw 0}, transfer-property=PENDING  # ASR NM Control Bit Vector - ASR NM Coordinator ID
          signal ISignal_BCAN_NM_OHCL_FD_CBV_NMCoSRB_OHCL_FD: start 11, 1 bit, little-endian, init-value=0, base-type=boolean, compu {phys=raw for raw 0}, transfer-property=PENDING  # ASR NM Control Bit Vector - ASR NM Coordinator Sleep Ready Bit
          signal ISignal_BCAN_NM_OHCL_FD_CBV_AWB_OHCL_FD: start 12, 1 bit, little-endian, init-value=0, base-type=boolean, compu {phys=raw for raw 0}, transfer-property=PENDING  # ASR NM Control Bit Vector - Active Wakeup Bit
          signal ISignal_BCAN_NM_OHCL_FD_CBV_PNIB_OHCL_FD: start 14, 1 bit, little-endian, init-value=0, base-type=boolean, compu {phys=raw for raw 0}, transfer-property=PENDING  # ASR NM Control Bit Vector - PN Info Bit
          signal ISignal_BCAN_NM_OHCL_FD_NRR_OHCL_FD: start 16, 8 bit, little-endian, init-value=0, base-type=uint8, compu {phys=raw for raw 0}, transfer-property=PENDING  # ASR NM Network Request Reason
          signal ISignal_BCAN_NM_OHCL_FD_NM_State_OHCL_FD: start 24, 8 bit, little-endian, init-value=0, base-type=uint8, compu {phys=raw for raw 0}, transfer-property=PENDING  # ASR NM State_Current State_Previous State
          signal ISignal_BCAN_NM_OHCL_FD_PNI_OHCL_FD: start 32, 32 bit, little-endian, init-value=0, base-type=uint32, compu {phys=raw for raw 0}, transfer-property=PENDING  # ASR NM Partial Networking Information
          signal ISignal_BCAN_NM_OHCL_FD_PNI_OHCL_FD_1: start 64, 64 bit, opaque, init-value=8 x 0, compu {phys=raw for raw 0}, implementation-data-type=array8uint8, transfer-property=PENDING  # ASR NM Partial Networking Information
          signal ISignal_BCAN_NM_OHCL_FD_PNI_OHCL_FD_2: start 128, 64 bit, opaque, init-value=8 x 0, compu {phys=raw for raw 0}, implementation-data-type=array8uint8, transfer-property=PENDING  # ASR NM Partial Networking Information
          signal ISignal_BCAN_NM_OHCL_FD_PNI_OHCL_FD_3: start 192, 64 bit, opaque, init-value=8 x 0, compu {phys=raw for raw 0}, implementation-data-type=array8uint8, transfer-property=PENDING  # ASR NM Partial Networking Information
      frame CanFrame_BCAN_NM_SHVU_REAR_FD: id 0x17FC00AB, frame-length=32, can-addressing-mode=EXTENDED, can-fd-frame-support=true
        nm pdu NmPdu_BCAN_NM_SHVU_REAR_FD: length=32
          signal ISignal_BCAN_NM_SHVU_REAR_FD_SNI_SHVU_REAR_FD: start 0, 8 bit, little-endian, init-value=0, base-type=uint8, compu {phys=raw for raw 0}, transfer-property=PENDING  # ASR NM Source Node Identifier
          signal ISignal_BCAN_NM_SHVU_REAR_FD_CBV_RMR_SHVU_REAR_FD: start 8, 1 bit, little-endian, init-value=0, base-type=boolean, compu {phys=raw for raw 0}, transfer-property=PENDING  # ASR NM Control Bit Vector - Repeat Message Request
          signal ISignal_BCAN_NM_SHVU_REAR_FD_CBV_NMCoID_SHVU_REAR_FD: start 9, 2 bit, little-endian, init-value=0, base-type=uint8, compu {phys=raw for raw 0}, transfer-property=PENDING  # ASR NM Control Bit Vector - ASR NM Coordinator ID
          signal ISignal_BCAN_NM_SHVU_REAR_FD_CBV_NMCoSRB_SHVU_REAR_FD: start 11, 1 bit, little-endian, init-value=0, base-type=boolean, compu {phys=raw for raw 0}, transfer-property=PENDING  # ASR NM Control Bit Vector - ASR NM Coordinator Sleep Ready Bit
          signal ISignal_BCAN_NM_SHVU_REAR_FD_CBV_AWB_SHVU_REAR_FD: start 12, 1 bit, little-endian, init-value=0, base-type=boolean, compu {phys=raw for raw 0}, transfer-property=PENDING  # ASR NM Control Bit Vector - Active Wakeup Bit
          signal ISignal_BCAN_NM_SHVU_REAR_FD_CBV_PNIB_SHVU_REAR_FD: start 14, 1 bit, little-endian, init-value=0, base-type=boolean, compu {phys=raw for raw 0}, transfer-property=PENDING  # ASR NM Control Bit Vector - PN Info Bit
          signal ISignal_BCAN_NM_SHVU_REAR_FD_NRR_SHVU_REAR_FD: start 16, 8 bit, little-endian, init-value=0, base-type=uint8, compu {phys=raw for raw 0}, transfer-property=PENDING  # ASR NM Network Request Reason
          signal ISignal_BCAN_NM_SHVU_REAR_FD_NM_State_SHVU_REAR_FD: start 24, 8 bit, little-endian, init-value=0, base-type=uint8, compu {phys=raw for raw 0}, transfer-property=PENDING  # ASR NM State_Current State_Previous State
          signal ISignal_BCAN_NM_SHVU_REAR_FD_PNI_SHVU_REAR_FD: start 32, 32 bit, little-endian, init-value=0, base-type=uint32, compu {phys=raw for raw 0}, transfer-property=PENDING  # ASR NM Partial Networking Information
          signal ISignal_BCAN_NM_SHVU_REAR_FD_PNI_SHVU_REAR_FD_1: start 64, 64 bit, opaque, init-value=8 x 0, compu {phys=raw for raw 0}, implementation-data-type=array8uint8, transfer-property=PENDING  # ASR NM Partial Networking Information
          signal ISignal_BCAN_NM_SHVU_REAR_FD_PNI_SHVU_REAR_FD_2: start 128, 64 bit, opaque, init-value=8 x 0, compu {phys=raw for raw 0}, implementation-data-type=array8uint8, transfer-property=PENDING  # ASR NM Partial Networking Information
          signal ISignal_BCAN_NM_SHVU_REAR_FD_PNI_SHVU_REAR_FD_3: start 192, 64 bit, opaque, init-value=8 x 0, compu {phys=raw for raw 0}, implementation-data-type=array8uint8, transfer-property=PENDING  # ASR NM Partial Networking Information
      frame CanFrame_BCAN_NM_BLTN_CAM_FD: id 0x17FC00C8, frame-length=32, can-addressing-mode=EXTENDED, can-fd-frame-support=true
        nm pdu NmPdu_BCAN_NM_BLTN_CAM_FD: length=32
          signal ISignal_BCAN_NM_BLTN_CAM_FD_SNI_BLTN_CAM_FD: start 0, 8 bit, little-endian, init-value=0, base-type=uint8, compu {phys=raw for raw 0}, transfer-property=PENDING  # ASR NM Source Node Identifier
          signal ISignal_BCAN_NM_BLTN_CAM_FD_CBV_RMR_BLTN_CAM_FD: start 8, 1 bit, little-endian, init-value=0, base-type=boolean, compu {phys=raw for raw 0}, transfer-property=PENDING  # ASR NM Control Bit Vector - Repeat Message Request
          signal ISignal_BCAN_NM_BLTN_CAM_FD_CBV_NMCoID_BLTN_CAM_FD: start 9, 2 bit, little-endian, init-value=0, base-type=uint8, compu {phys=raw for raw 0}, transfer-property=PENDING  # ASR NM Control Bit Vector - ASR NM Coordinator ID
          signal ISignal_BCAN_NM_BLTN_CAM_FD_CBV_NMCoSRB_BLTN_CAM_FD: start 11, 1 bit, little-endian, init-value=0, base-type=boolean, compu {phys=raw for raw 0}, transfer-property=PENDING  # ASR NM Control Bit Vector - ASR NM Coordinator Sleep Ready Bit
          signal ISignal_BCAN_NM_BLTN_CAM_FD_CBV_AWB_BLTN_CAM_FD: start 12, 1 bit, little-endian, init-value=0, base-type=boolean, compu {phys=raw for raw 0}, transfer-property=PENDING  # ASR NM Control Bit Vector - Active Wakeup Bit
          signal ISignal_BCAN_NM_BLTN_CAM_FD_CBV_PNIB_BLTN_CAM_FD: start 14, 1 bit, little-endian, init-value=0, base-type=boolean, compu {phys=raw for raw 0}, transfer-property=PENDING  # ASR NM Control Bit Vector - PN Info Bit
          signal ISignal_BCAN_NM_BLTN_CAM_FD_NRR_BLTN_CAM_FD: start 16, 8 bit, little-endian, init-value=0, base-type=uint8, compu {phys=raw for raw 0}, transfer-property=PENDING  # ASR NM Network Request Reason
          signal ISignal_BCAN_NM_BLTN_CAM_FD_NM_State_BLTN_CAM_FD: start 24, 8 bit, little-endian, init-value=0, base-type=uint8, compu {phys=raw for raw 0}, transfer-property=PENDING  # ASR NM State_Current State_Previous State
          signal ISignal_BCAN_NM_BLTN_CAM_FD_PNI_BLTN_CAM_FD: start 32, 32 bit, little-endian, init-value=0, base-type=uint32, compu {phys=raw for raw 0}, transfer-property=PENDING  # ASR NM Partial Networking Information
          signal ISignal_BCAN_NM_BLTN_CAM_FD_PNI_BLTN_CAM_FD_1: start 64, 64 bit, opaque, init-value=8 x 0, compu {phys=raw for raw 0}, implementation-data-type=array8uint8, transfer-property=PENDING  # ASR NM Partial Networking Information
          signal ISignal_BCAN_NM_BLTN_CAM_FD_PNI_BLTN_CAM_FD_2: start 128, 64 bit, opaque, init-value=8 x 0, compu {phys=raw for raw 0}, implementation-data-type=array8uint8, transfer-property=PENDING  # ASR NM Partial Networking Information
          signal ISignal_BCAN_NM_BLTN_CAM_FD_PNI_BLTN_CAM_FD_3: start 192, 64 bit, opaque, init-value=8 x 0, compu {phys=raw for raw 0}, implementation-data-type=array8uint8, transfer-property=PENDING  # ASR NM Partial Networking Information
      frame CanFrame_BCAN_NM_GW_PSU_DRV_FD: id 0x17FC00B8, frame-length=32, can-addressing-mode=EXTENDED, can-fd-frame-support=true
        nm pdu NmPdu_BCAN_NM_GW_PSU_DRV_FD: length=32
          signal ISignal_BCAN_NM_GW_PSU_DRV_FD_SNI_GW_PSU_DRV_FD: start 0, 8 bit, little-endian, init-value=0, base-type=uint8, compu {phys=raw for raw 0}, transfer-property=PENDING  # ASR NM Source Node Identifier
          signal ISignal_BCAN_NM_GW_PSU_DRV_FD_CBV_RMR_GW_PSU_DRV_FD: start 8, 1 bit, little-endian, init-value=0, base-type=boolean, compu {phys=raw for raw 0}, transfer-property=PENDING  # ASR NM Control Bit Vector - Repeat Message Request
          signal ISignal_BCAN_NM_GW_PSU_DRV_FD_CBV_NMCoID_GW_PSU_DRV_FD: start 9, 2 bit, little-endian, init-value=0, base-type=uint8, compu {phys=raw for raw 0}, transfer-property=PENDING  # ASR NM Control Bit Vector - ASR NM Coordinator ID
          signal ISignal_BCAN_NM_GW_PSU_DRV_FD_CBV_NMCoSRB_GW_PSU_DRV_FD: start 11, 1 bit, little-endian, init-value=0, base-type=boolean, compu {phys=raw for raw 0}, transfer-property=PENDING  # ASR NM Control Bit Vector - ASR NM Coordinator Sleep Ready Bit
          signal ISignal_BCAN_NM_GW_PSU_DRV_FD_CBV_AWB_GW_PSU_DRV_FD: start 12, 1 bit, little-endian, init-value=0, base-type=boolean, compu {phys=raw for raw 0}, transfer-property=PENDING  # ASR NM Control Bit Vector - Active Wakeup Bit
          signal ISignal_BCAN_NM_GW_PSU_DRV_FD_CBV_PNIB_GW_PSU_DRV_FD: start 14, 1 bit, little-endian, init-value=0, base-type=boolean, compu {phys=raw for raw 0}, transfer-property=PENDING  # ASR NM Control Bit Vector - PN Info Bit
          signal ISignal_BCAN_NM_GW_PSU_DRV_FD_NRR_GW_PSU_DRV_FD: start 16, 8 bit, little-endian, init-value=0, base-type=uint8, compu {phys=raw for raw 0}, transfer-property=PENDING  # ASR NM Network Request Reason
          signal ISignal_BCAN_NM_GW_PSU_DRV_FD_NM_State_GW_PSU_DRV_FD: start 24, 8 bit, little-endian, init-value=0, base-type=uint8, compu {phys=raw for raw 0}, transfer-property=PENDING  # ASR NM State_Current State_Previous State
          signal ISignal_BCAN_NM_GW_PSU_DRV_FD_PNI_GW_PSU_DRV_FD: start 32, 32 bit, little-endian, init-value=0, base-type=uint32, compu {phys=raw for raw 0}, transfer-property=PENDING  # ASR NM Partial Networking Information
          signal ISignal_BCAN_NM_GW_PSU_DRV_FD_PNI_GW_PSU_DRV_FD_1: start 64, 64 bit, opaque, init-value=8 x 0, compu {phys=raw for raw 0}, implementation-data-type=array8uint8, transfer-property=PENDING  # ASR NM Partial Networking Information
          signal ISignal_BCAN_NM_GW_PSU_DRV_FD_PNI_GW_PSU_DRV_FD_2: start 128, 64 bit, opaque, init-value=8 x 0, compu {phys=raw for raw 0}, implementation-data-type=array8uint8, transfer-property=PENDING  # ASR NM Partial Networking Information
          signal ISignal_BCAN_NM_GW_PSU_DRV_FD_PNI_GW_PSU_DRV_FD_3: start 192, 64 bit, opaque, init-value=8 x 0, compu {phys=raw for raw 0}, implementation-data-type=array8uint8, transfer-property=PENDING  # ASR NM Partial Networking Information
      frame CanFrame_BCAN_NM_FCS_FD: id 0x17FC00A1, frame-length=32, can-addressing-mode=EXTENDED, can-fd-frame-support=true
        nm pdu NmPdu_BCAN_NM_FCS_FD: length=32
          signal ISignal_BCAN_NM_FCS_FD_SNI_FCS_FD: start 0, 8 bit, little-endian, init-value=0, base-type=uint8, compu {phys=raw for raw 0}, transfer-property=PENDING  # ASR NM Source Node Identifier
          signal ISignal_BCAN_NM_FCS_FD_CBV_RMR_FCS_FD: start 8, 1 bit, little-endian, init-value=0, base-type=boolean, compu {phys=raw for raw 0}, transfer-property=PENDING  # ASR NM Control Bit Vector - Repeat Message Request
          signal ISignal_BCAN_NM_FCS_FD_CBV_NMCoID_FCS_FD: start 9, 2 bit, little-endian, init-value=0, base-type=uint8, compu {phys=raw for raw 0}, transfer-property=PENDING  # ASR NM Control Bit Vector - ASR NM Coordinator ID
          signal ISignal_BCAN_NM_FCS_FD_CBV_NMCoSRB_FCS_FD: start 11, 1 bit, little-endian, init-value=0, base-type=boolean, compu {phys=raw for raw 0}, transfer-property=PENDING  # ASR NM Control Bit Vector - ASR NM Coordinator Sleep Ready Bit
          signal ISignal_BCAN_NM_FCS_FD_CBV_AWB_FCS_FD: start 12, 1 bit, little-endian, init-value=0, base-type=boolean, compu {phys=raw for raw 0}, transfer-property=PENDING  # ASR NM Control Bit Vector - Active Wakeup Bit
          signal ISignal_BCAN_NM_FCS_FD_CBV_PNIB_FCS_FD: start 14, 1 bit, little-endian, init-value=0, base-type=boolean, compu {phys=raw for raw 0}, transfer-property=PENDING  # ASR NM Control Bit Vector - PN Info Bit
          signal ISignal_BCAN_NM_FCS_FD_NRR_FCS_FD: start 16, 8 bit, little-endian, init-value=0, base-type=uint8, compu {phys=raw for raw 0}, transfer-property=PENDING  # ASR NM Network Request Reason
          signal ISignal_BCAN_NM_FCS_FD_NM_State_FCS_FD: start 24, 8 bit, little-endian, init-value=0, base-type=uint8, compu {phys=raw for raw 0}, transfer-property=PENDING  # ASR NM State_Current State_Previous State
          signal ISignal_BCAN_NM_FCS_FD_PNI_FCS_FD: start 32, 32 bit, little-endian, init-value=0, base-type=uint32, compu {phys=raw for raw 0}, transfer-property=PENDING  # ASR NM Partial Networking Information
          signal ISignal_BCAN_NM_FCS_FD_PNI_FCS_FD_1: start 64, 64 bit, opaque, init-value=8 x 0, compu {phys=raw for raw 0}, implementation-data-type=array8uint8, transfer-property=PENDING  # ASR NM Partial Networking Information
          signal ISignal_BCAN_NM_FCS_FD_PNI_FCS_FD_2: start 128, 64 bit, opaque, init-value=8 x 0, compu {phys=raw for raw 0}, implementation-data-type=array8uint8, transfer-property=PENDING  # ASR NM Partial Networking Information
          signal ISignal_BCAN_NM_FCS_FD_PNI_FCS_FD_3: start 192, 64 bit, opaque, init-value=8 x 0, compu {phys=raw for raw 0}, implementation-data-type=array8uint8, transfer-property=PENDING  # ASR NM Partial Networking Information
      frame CanFrame_BCAN_NM_GW_PSU_AST_FD: id 0x17FC00B1, frame-length=32, can-addressing-mode=EXTENDED, can-fd-frame-support=true
        nm pdu NmPdu_BCAN_NM_GW_PSU_AST_FD: length=32
          signal ISignal_BCAN_NM_GW_PSU_AST_FD_SNI_GW_PSU_AST_FD: start 0, 8 bit, little-endian, init-value=0, base-type=uint8, compu {phys=raw for raw 0}, transfer-property=PENDING  # ASR NM Source Node Identifier
          signal ISignal_BCAN_NM_GW_PSU_AST_FD_CBV_RMR_GW_PSU_AST_FD: start 8, 1 bit, little-endian, init-value=0, base-type=boolean, compu {phys=raw for raw 0}, transfer-property=PENDING  # ASR NM Control Bit Vector - Repeat Message Request
          signal ISignal_BCAN_NM_GW_PSU_AST_FD_CBV_NMCoID_GW_PSU_AST_FD: start 9, 2 bit, little-endian, init-value=0, base-type=uint8, compu {phys=raw for raw 0}, transfer-property=PENDING  # ASR NM Control Bit Vector - ASR NM Coordinator ID
          signal ISignal_BCAN_NM_GW_PSU_AST_FD_CBV_NMCoSRB_GW_PSU_AST_FD: start 11, 1 bit, little-endian, init-value=0, base-type=boolean, compu {phys=raw for raw 0}, transfer-property=PENDING  # ASR NM Control Bit Vector - ASR NM Coordinator Sleep Ready Bit
          signal ISignal_BCAN_NM_GW_PSU_AST_FD_CBV_AWB_GW_PSU_AST_FD: start 12, 1 bit, little-endian, init-value=0, base-type=boolean, compu {phys=raw for raw 0}, transfer-property=PENDING  # ASR NM Control Bit Vector - Active Wakeup Bit
          signal ISignal_BCAN_NM_GW_PSU_AST_FD_CBV_PNIB_GW_PSU_AST_FD: start 14, 1 bit, little-endian, init-value=0, base-type=boolean, compu {phys=raw for raw 0}, transfer-property=PENDING  # ASR NM Control Bit Vector - PN Info Bit
          signal ISignal_BCAN_NM_GW_PSU_AST_FD_NRR_GW_PSU_AST_FD: start 16, 8 bit, little-endian, init-value=0, base-type=uint8, compu {phys=raw for raw 0}, transfer-property=PENDING  # ASR NM Network Request Reason
          signal ISignal_BCAN_NM_GW_PSU_AST_FD_NM_State_GW_PSU_AST_FD: start 24, 8 bit, little-endian, init-value=0, base-type=uint8, compu {phys=raw for raw 0}, transfer-property=PENDING  # ASR NM State_Current State_Previous State
          signal ISignal_BCAN_NM_GW_PSU_AST_FD_PNI_GW_PSU_AST_FD: start 32, 32 bit, little-endian, init-value=0, base-type=uint32, compu {phys=raw for raw 0}, transfer-property=PENDING  # ASR NM Partial Networking Information
          signal ISignal_BCAN_NM_GW_PSU_AST_FD_PNI_GW_PSU_AST_FD_1: start 64, 64 bit, opaque, init-value=8 x 0, compu {phys=raw for raw 0}, implementation-data-type=array8uint8, transfer-property=PENDING  # ASR NM Partial Networking Information
          signal ISignal_BCAN_NM_GW_PSU_AST_FD_PNI_GW_PSU_AST_FD_2: start 128, 64 bit, opaque, init-value=8 x 0, compu {phys=raw for raw 0}, implementation-data-type=array8uint8, transfer-property=PENDING  # ASR NM Partial Networking Information
          signal ISignal_BCAN_NM_GW_PSU_AST_FD_PNI_GW_PSU_AST_FD_3: start 192, 64 bit, opaque, init-value=8 x 0, compu {phys=raw for raw 0}, implementation-data-type=array8uint8, transfer-property=PENDING  # ASR NM Partial Networking Information
      frame CanFrame_BCAN_NM_GW_PSU_3RD_FD: id 0x17FC00AD, frame-length=32, can-addressing-mode=EXTENDED, can-fd-frame-support=true
        nm pdu NmPdu_BCAN_NM_GW_PSU_3RD_FD: length=32
          signal ISignal_BCAN_NM_GW_PSU_3RD_FD_SNI_GW_PSU_3RD_FD: start 0, 8 bit, little-endian, init-value=0, base-type=uint8, compu {phys=raw for raw 0}, transfer-property=PENDING  # ASR NM Source Node Identifier
          signal ISignal_BCAN_NM_GW_PSU_3RD_FD_CBV_RMR_GW_PSU_3RD_FD: start 8, 1 bit, little-endian, init-value=0, base-type=boolean, compu {phys=raw for raw 0}, transfer-property=PENDING  # ASR NM Control Bit Vector - Repeat Message Request
          signal ISignal_BCAN_NM_GW_PSU_3RD_FD_CBV_NMCoID_GW_PSU_3RD_FD: start 9, 2 bit, little-endian, init-value=0, base-type=uint8, compu {phys=raw for raw 0}, transfer-property=PENDING  # ASR NM Control Bit Vector - ASR NM Coordinator ID
          signal ISignal_BCAN_NM_GW_PSU_3RD_FD_CBV_NMCoSRB_GW_PSU_3RD_FD: start 11, 1 bit, little-endian, init-value=0, base-type=boolean, compu {phys=raw for raw 0}, transfer-property=PENDING  # ASR NM Control Bit Vector - ASR NM Coordinator Sleep Ready Bit
          signal ISignal_BCAN_NM_GW_PSU_3RD_FD_CBV_AWB_GW_PSU_3RD_FD: start 12, 1 bit, little-endian, init-value=0, base-type=boolean, compu {phys=raw for raw 0}, transfer-property=PENDING  # ASR NM Control Bit Vector - Active Wakeup Bit
          signal ISignal_BCAN_NM_GW_PSU_3RD_FD_CBV_PNIB_GW_PSU_3RD_FD: start 14, 1 bit, little-endian, init-value=0, base-type=boolean, compu {phys=raw for raw 0}, transfer-property=PENDING  # ASR NM Control Bit Vector - PN Info Bit
          signal ISignal_BCAN_NM_GW_PSU_3RD_FD_NRR_GW_PSU_3RD_FD: start 16, 8 bit, little-endian, init-value=0, base-type=uint8, compu {phys=raw for raw 0}, transfer-property=PENDING  # ASR NM Network Request Reason
          signal ISignal_BCAN_NM_GW_PSU_3RD_FD_NM_State_GW_PSU_3RD_FD: start 24, 8 bit, little-endian, init-value=0, base-type=uint8, compu {phys=raw for raw 0}, transfer-property=PENDING  # ASR NM State_Current State_Previous State
          signal ISignal_BCAN_NM_GW_PSU_3RD_FD_PNI_GW_PSU_3RD_FD: start 32, 32 bit, little-endian, init-value=0, base-type=uint32, compu {phys=raw for raw 0}, transfer-property=PENDING  # ASR NM Partial Networking Information
          signal ISignal_BCAN_NM_GW_PSU_3RD_FD_PNI_GW_PSU_3RD_FD_1: start 64, 64 bit, opaque, init-value=8 x 0, compu {phys=raw for raw 0}, implementation-data-type=array8uint8, transfer-property=PENDING  # ASR NM Partial Networking Information
          signal ISignal_BCAN_NM_GW_PSU_3RD_FD_PNI_GW_PSU_3RD_FD_2: start 128, 64 bit, opaque, init-value=8 x 0, compu {phys=raw for raw 0}, implementation-data-type=array8uint8, transfer-property=PENDING  # ASR NM Partial Networking Information
          signal ISignal_BCAN_NM_GW_PSU_3RD_FD_PNI_GW_PSU_3RD_FD_3: start 192, 64 bit, opaque, init-value=8 x 0, compu {phys=raw for raw 0}, implementation-data-type=array8uint8, transfer-property=PENDING  # ASR NM Partial Networking Information
      frame CanFrame_BCAN_NM_RCS_FD: id 0x17FC00C6, frame-length=32, can-addressing-mode=EXTENDED, can-fd-frame-support=true
        nm pdu NmPdu_BCAN_NM_RCS_FD: length=32
          signal ISignal_BCAN_NM_RCS_FD_SNI_RCS_FD: start 0, 8 bit, little-endian, init-value=0, base-type=uint8, compu {phys=raw for raw 0}, transfer-property=PENDING  # ASR NM Source Node Identifier
          signal ISignal_BCAN_NM_RCS_FD_CBV_RMR_RCS_FD: start 8, 1 bit, little-endian, init-value=0, base-type=boolean, compu {phys=raw for raw 0}, transfer-property=PENDING  # ASR NM Control Bit Vector - Repeat Message Request
          signal ISignal_BCAN_NM_RCS_FD_CBV_NMCoID_RCS_FD: start 9, 2 bit, little-endian, init-value=0, base-type=uint8, compu {phys=raw for raw 0}, transfer-property=PENDING  # ASR NM Control Bit Vector - ASR NM Coordinator ID
          signal ISignal_BCAN_NM_RCS_FD_CBV_NMCoSRB_RCS_FD: start 11, 1 bit, little-endian, init-value=0, base-type=boolean, compu {phys=raw for raw 0}, transfer-property=PENDING  # ASR NM Control Bit Vector - ASR NM Coordinator Sleep Ready Bit
          signal ISignal_BCAN_NM_RCS_FD_CBV_AWB_RCS_FD: start 12, 1 bit, little-endian, init-value=0, base-type=boolean, compu {phys=raw for raw 0}, transfer-property=PENDING  # ASR NM Control Bit Vector - Active Wakeup Bit
          signal ISignal_BCAN_NM_RCS_FD_CBV_PNIB_RCS_FD: start 14, 1 bit, little-endian, init-value=0, base-type=boolean, compu {phys=raw for raw 0}, transfer-property=PENDING  # ASR NM Control Bit Vector - PN Info Bit
          signal ISignal_BCAN_NM_RCS_FD_NRR_RCS_FD: start 16, 8 bit, little-endian, init-value=0, base-type=uint8, compu {phys=raw for raw 0}, transfer-property=PENDING  # ASR NM Network Request Reason
          signal ISignal_BCAN_NM_RCS_FD_NM_State_RCS_FD: start 24, 8 bit, little-endian, init-value=0, base-type=uint8, compu {phys=raw for raw 0}, transfer-property=PENDING  # ASR NM State_Current State_Previous State
          signal ISignal_BCAN_NM_RCS_FD_PNI_RCS_FD: start 32, 32 bit, little-endian, init-value=0, base-type=uint32, compu {phys=raw for raw 0}, transfer-property=PENDING  # ASR NM Partial Networking Information
          signal ISignal_BCAN_NM_RCS_FD_PNI_RCS_FD_1: start 64, 64 bit, opaque, init-value=8 x 0, compu {phys=raw for raw 0}, implementation-data-type=array8uint8, transfer-property=PENDING  # ASR NM Partial Networking Information
          signal ISignal_BCAN_NM_RCS_FD_PNI_RCS_FD_2: start 128, 64 bit, opaque, init-value=8 x 0, compu {phys=raw for raw 0}, implementation-data-type=array8uint8, transfer-property=PENDING  # ASR NM Partial Networking Information
          signal ISignal_BCAN_NM_RCS_FD_PNI_RCS_FD_3: start 192, 64 bit, opaque, init-value=8 x 0, compu {phys=raw for raw 0}, implementation-data-type=array8uint8, transfer-property=PENDING  # ASR NM Partial Networking Information
      frame CanFrame_BCAN_NM_RCM_FD: id 0x17FC00BD, frame-length=32, can-addressing-mode=EXTENDED, can-fd-frame-support=true
        nm pdu NmPdu_BCAN_NM_RCM_FD: length=32
          signal ISignal_BCAN_NM_RCM_FD_SNI_RCM_FD: start 0, 8 bit, little-endian, init-value=0, base-type=uint8, compu {phys=raw for raw 0}, transfer-property=PENDING  # ASR NM Source Node Identifier
          signal ISignal_BCAN_NM_RCM_FD_CBV_RMR_RCM_FD: start 8, 1 bit, little-endian, init-value=0, base-type=boolean, compu {phys=raw for raw 0}, transfer-property=PENDING  # ASR NM Control Bit Vector - Repeat Message Request
          signal ISignal_BCAN_NM_RCM_FD_CBV_NMCoID_RCM_FD: start 9, 2 bit, little-endian, init-value=0, base-type=uint8, compu {phys=raw for raw 0}, transfer-property=PENDING  # ASR NM Control Bit Vector - ASR NM Coordinator ID
          signal ISignal_BCAN_NM_RCM_FD_CBV_NMCoSRB_RCM_FD: start 11, 1 bit, little-endian, init-value=0, base-type=boolean, compu {phys=raw for raw 0}, transfer-property=PENDING  # ASR NM Control Bit Vector - ASR NM Coordinator Sleep Ready Bit
          signal ISignal_BCAN_NM_RCM_FD_CBV_AWB_RCM_FD: start 12, 1 bit, little-endian, init-value=0, base-type=boolean, compu {phys=raw for raw 0}, transfer-property=PENDING  # ASR NM Control Bit Vector - Active Wakeup Bit
          signal ISignal_BCAN_NM_RCM_FD_CBV_PNIB_RCM_FD: start 14, 1 bit, little-endian, init-value=0, base-type=boolean, compu {phys=raw for raw 0}, transfer-property=PENDING  # ASR NM Control Bit Vector - PN Info Bit
          signal ISignal_BCAN_NM_RCM_FD_NRR_RCM_FD: start 16, 8 bit, little-endian, init-value=0, base-type=uint8, compu {phys=raw for raw 0}, transfer-property=PENDING  # ASR NM Network Request Reason
          signal ISignal_BCAN_NM_RCM_FD_NM_State_RCM_FD: start 24, 8 bit, little-endian, init-value=0, base-type=uint8, compu {phys=raw for raw 0}, transfer-property=PENDING  # ASR NM State_Current State_Previous State
          signal ISignal_BCAN_NM_RCM_FD_PNI_RCM_FD: start 32, 32 bit, little-endian, init-value=0, base-type=uint32, compu {phys=raw for raw 0}, transfer-property=PENDING  # ASR NM Partial Networking Information
          signal ISignal_BCAN_NM_RCM_FD_PNI_RCM_FD_1: start 64, 64 bit, opaque, init-value=8 x 0, compu {phys=raw for raw 0}, implementation-data-type=array8uint8, transfer-property=PENDING  # ASR NM Partial Networking Information
          signal ISignal_BCAN_NM_RCM_FD_PNI_RCM_FD_2: start 128, 64 bit, opaque, init-value=8 x 0, compu {phys=raw for raw 0}, implementation-data-type=array8uint8, transfer-property=PENDING  # ASR NM Partial Networking Information
          signal ISignal_BCAN_NM_RCM_FD_PNI_RCM_FD_3: start 192, 64 bit, opaque, init-value=8 x 0, compu {phys=raw for raw 0}, implementation-data-type=array8uint8, transfer-property=PENDING  # ASR NM Partial Networking Information
      frame CanFrame_BCAN_NM_GW_PSU_RL_FD: id 0x17FC009C, frame-length=32, can-addressing-mode=EXTENDED, can-fd-frame-support=true
        nm pdu NmPdu_BCAN_NM_GW_PSU_RL_FD: length=32
          signal ISignal_BCAN_NM_GW_PSU_RL_FD_SNI_GW_PSU_RL_FD: start 0, 8 bit, little-endian, init-value=0, base-type=uint8, compu {phys=raw for raw 0}, transfer-property=PENDING  # ASR NM Source Node Identifier
          signal ISignal_BCAN_NM_GW_PSU_RL_FD_CBV_RMR_GW_PSU_RL_FD: start 8, 1 bit, little-endian, init-value=0, base-type=boolean, compu {phys=raw for raw 0}, transfer-property=PENDING  # ASR NM Control Bit Vector - Repeat Message Request
          signal ISignal_BCAN_NM_GW_PSU_RL_FD_CBV_NMCoID_GW_PSU_RL_FD: start 9, 2 bit, little-endian, init-value=0, base-type=uint8, compu {phys=raw for raw 0}, transfer-property=PENDING  # ASR NM Control Bit Vector - ASR NM Coordinator ID
          signal ISignal_BCAN_NM_GW_PSU_RL_FD_CBV_NMCoSRB_GW_PSU_RL_FD: start 11, 1 bit, little-endian, init-value=0, base-type=boolean, compu {phys=raw for raw 0}, transfer-property=PENDING  # ASR NM Control Bit Vector - ASR NM Coordinator Sleep Ready Bit
          signal ISignal_BCAN_NM_GW_PSU_RL_FD_CBV_AWB_GW_PSU_RL_FD: start 12, 1 bit, little-endian, init-value=0, base-type=boolean, compu {phys=raw for raw 0}, transfer-property=PENDING  # ASR NM Control Bit Vector - Active Wakeup Bit
          signal ISignal_BCAN_NM_GW_PSU_RL_FD_CBV_PNIB_GW_PSU_RL_FD: start 14, 1 bit, little-endian, init-value=0, base-type=boolean, compu {phys=raw for raw 0}, transfer-property=PENDING  # ASR NM Control Bit Vector - PN Info Bit
          signal ISignal_BCAN_NM_GW_PSU_RL_FD_NRR_GW_PSU_RL_FD: start 16, 8 bit, little-endian, init-value=0, base-type=uint8, compu {phys=raw for raw 0}, transfer-property=PENDING  # ASR NM Network Request Reason
          signal ISignal_BCAN_NM_GW_PSU_RL_FD_NM_State_GW_PSU_RL_FD: start 24, 8 bit, little-endian, init-value=0, base-type=uint8, compu {phys=raw for raw 0}, transfer-property=PENDING  # ASR NM State_Current State_Previous State
          signal ISignal_BCAN_NM_GW_PSU_RL_FD_PNI_GW_PSU_RL_FD: start 32, 32 bit, little-endian, init-value=0, base-type=uint32, compu {phys=raw for raw 0}, transfer-property=PENDING  # ASR NM Partial Networking Information
          signal ISignal_BCAN_NM_GW_PSU_RL_FD_PNI_GW_PSU_RL_FD_1: start 64, 64 bit, opaque, init-value=8 x 0, compu {phys=raw for raw 0}, implementation-data-type=array8uint8, transfer-property=PENDING  # ASR NM Partial Networking Information
          signal ISignal_BCAN_NM_GW_PSU_RL_FD_PNI_GW_PSU_RL_FD_2: start 128, 64 bit, opaque, init-value=8 x 0, compu {phys=raw for raw 0}, implementation-data-type=array8uint8, transfer-property=PENDING  # ASR NM Partial Networking Information
          signal ISignal_BCAN_NM_GW_PSU_RL_FD_PNI_GW_PSU_RL_FD_3: start 192, 64 bit, opaque, init-value=8 x 0, compu {phys=raw for raw 0}, implementation-data-type=array8uint8, transfer-property=PENDING  # ASR NM Partial Networking Information
      frame CanFrame_BCAN_NM_SHVU_RR_FD: id 0x17FC00B5, frame-length=32, can-addressing-mode=EXTENDED, can-fd-frame-support=true
        nm pdu NmPdu_BCAN_NM_SHVU_RR_FD: length=32
          signal ISignal_BCAN_NM_SHVU_RR_FD_SNI_SHVU_RR_FD: start 0, 8 bit, little-endian, init-value=0, base-type=uint8, compu {phys=raw for raw 0}, transfer-property=PENDING  # ASR NM Source Node Identifier
          signal ISignal_BCAN_NM_SHVU_RR_FD_CBV_RMR_SHVU_RR_FD: start 8, 1 bit, little-endian, init-value=0, base-type=boolean, compu {phys=raw for raw 0}, transfer-property=PENDING  # ASR NM Control Bit Vector - Repeat Message Request
          signal ISignal_BCAN_NM_SHVU_RR_FD_CBV_NMCoID_SHVU_RR_FD: start 9, 2 bit, little-endian, init-value=0, base-type=uint8, compu {phys=raw for raw 0}, transfer-property=PENDING  # ASR NM Control Bit Vector - ASR NM Coordinator ID
          signal ISignal_BCAN_NM_SHVU_RR_FD_CBV_NMCoSRB_SHVU_RR_FD: start 11, 1 bit, little-endian, init-value=0, base-type=boolean, compu {phys=raw for raw 0}, transfer-property=PENDING  # ASR NM Control Bit Vector - ASR NM Coordinator Sleep Ready Bit
          signal ISignal_BCAN_NM_SHVU_RR_FD_CBV_AWB_SHVU_RR_FD: start 12, 1 bit, little-endian, init-value=0, base-type=boolean, compu {phys=raw for raw 0}, transfer-property=PENDING  # ASR NM Control Bit Vector - Active Wakeup Bit
          signal ISignal_BCAN_NM_SHVU_RR_FD_CBV_PNIB_SHVU_RR_FD: start 14, 1 bit, little-endian, init-value=0, base-type=boolean, compu {phys=raw for raw 0}, transfer-property=PENDING  # ASR NM Control Bit Vector - PN Info Bit
          signal ISignal_BCAN_NM_SHVU_RR_FD_NRR_SHVU_RR_FD: start 16, 8 bit, little-endian, init-value=0, base-type=uint8, compu {phys=raw for raw 0}, transfer-property=PENDING  # ASR NM Network Request Reason
          signal ISignal_BCAN_NM_SHVU_RR_FD_NM_State_SHVU_RR_FD: start 24, 8 bit, little-endian, init-value=0, base-type=uint8, compu {phys=raw for raw 0}, transfer-property=PENDING  # ASR NM State_Current State_Previous State
          signal ISignal_BCAN_NM_SHVU_RR_FD_PNI_SHVU_RR_FD: start 32, 32 bit, little-endian, init-value=0, base-type=uint32, compu {phys=raw for raw 0}, transfer-property=PENDING  # ASR NM Partial Networking Information
          signal ISignal_BCAN_NM_SHVU_RR_FD_PNI_SHVU_RR_FD_1: start 64, 64 bit, opaque, init-value=8 x 0, compu {phys=raw for raw 0}, implementation-data-type=array8uint8, transfer-property=PENDING  # ASR NM Partial Networking Information
          signal ISignal_BCAN_NM_SHVU_RR_FD_PNI_SHVU_RR_FD_2: start 128, 64 bit, opaque, init-value=8 x 0, compu {phys=raw for raw 0}, implementation-data-type=array8uint8, transfer-property=PENDING  # ASR NM Partial Networking Information
          signal ISignal_BCAN_NM_SHVU_RR_FD_PNI_SHVU_RR_FD_3: start 192, 64 bit, opaque, init-value=8 x 0, compu {phys=raw for raw 0}, implementation-data-type=array8uint8, transfer-property=PENDING  # ASR NM Partial Networking Information
      frame CanFrame_BCAN_NM_SHVU_3RD_FD: id 0x17FC0052, frame-length=32, can-addressing-mode=EXTENDED, can-fd-frame-support=true
        nm pdu NmPdu_BCAN_NM_SHVU_3RD_FD: length=32
          signal ISignal_BCAN_NM_SHVU_3RD_FD_SNI_SHVU_3RD_FD: start 0, 8 bit, little-endian, init-value=0, base-type=uint8, compu {phys=raw for raw 0}, transfer-property=PENDING  # ASR NM Source Node Identifier
          signal ISignal_BCAN_NM_SHVU_3RD_FD_CBV_RMR_SHVU_3RD_FD: start 8, 1 bit, little-endian, init-value=0, base-type=boolean, compu {phys=raw for raw 0}, transfer-property=PENDING  # ASR NM Control Bit Vector - Repeat Message Request
          signal ISignal_BCAN_NM_SHVU_3RD_FD_CBV_NMCoID_SHVU_3RD_FD: start 9, 2 bit, little-endian, init-value=0, base-type=uint8, compu {phys=raw for raw 0}, transfer-property=PENDING  # ASR NM Control Bit Vector - ASR NM Coordinator ID
          signal ISignal_BCAN_NM_SHVU_3RD_FD_CBV_NMCoSRB_SHVU_3RD_FD: start 11, 1 bit, little-endian, init-value=0, base-type=boolean, compu {phys=raw for raw 0}, transfer-property=PENDING  # ASR NM Control Bit Vector - ASR NM Coordinator Sleep Ready Bit
          signal ISignal_BCAN_NM_SHVU_3RD_FD_CBV_AWB_SHVU_3RD_FD: start 12, 1 bit, little-endian, init-value=0, base-type=boolean, compu {phys=raw for raw 0}, transfer-property=PENDING  # ASR NM Control Bit Vector - Active Wakeup Bit
          signal ISignal_BCAN_NM_SHVU_3RD_FD_CBV_PNIB_SHVU_3RD_FD: start 14, 1 bit, little-endian, init-value=0, base-type=boolean, compu {phys=raw for raw 0}, transfer-property=PENDING  # ASR NM Control Bit Vector - PN Info Bit
          signal ISignal_BCAN_NM_SHVU_3RD_FD_NRR_SHVU_3RD_FD: start 16, 8 bit, little-endian, init-value=0, base-type=uint8, compu {phys=raw for raw 0}, transfer-property=PENDING  # ASR NM Network Request Reason
          signal ISignal_BCAN_NM_SHVU_3RD_FD_NM_State_SHVU_3RD_FD: start 24, 8 bit, little-endian, init-value=0, base-type=uint8, compu {phys=raw for raw 0}, transfer-property=PENDING  # ASR NM State_Current State_Previous State
          signal ISignal_BCAN_NM_SHVU_3RD_FD_PNI_SHVU_3RD_FD: start 32, 32 bit, little-endian, init-value=0, base-type=uint32, compu {phys=raw for raw 0}, transfer-property=PENDING  # ASR NM Partial Networking Information
          signal ISignal_BCAN_NM_SHVU_3RD_FD_PNI_SHVU_3RD_FD_1: start 64, 64 bit, opaque, init-value=8 x 0, compu {phys=raw for raw 0}, implementation-data-type=array8uint8, transfer-property=PENDING  # ASR NM Partial Networking Information
          signal ISignal_BCAN_NM_SHVU_3RD_FD_PNI_SHVU_3RD_FD_2: start 128, 64 bit, opaque, init-value=8 x 0, compu {phys=raw for raw 0}, implementation-data-type=array8uint8, transfer-property=PENDING  # ASR NM Partial Networking Information
          signal ISignal_BCAN_NM_SHVU_3RD_FD_PNI_SHVU_3RD_FD_3: start 192, 64 bit, opaque, init-value=8 x 0, compu {phys=raw for raw 0}, implementation-data-type=array8uint8, transfer-property=PENDING  # ASR NM Partial Networking Information
      frame CanFrame_BCAN_NM_SGU_FD: id 0x17FC00BE, frame-length=32, can-addressing-mode=EXTENDED, can-fd-frame-support=true
        nm pdu NmPdu_BCAN_NM_SGU_FD: length=32
          signal ISignal_BCAN_NM_SGU_FD_SNI_SGU_FD: start 0, 8 bit, little-endian, init-value=0, base-type=uint8, compu {phys=raw for raw 0}, transfer-property=PENDING  # ASR NM Source Node Identifier
          signal ISignal_BCAN_NM_SGU_FD_CBV_RMR_SGU_FD: start 8, 1 bit, little-endian, init-value=0, base-type=boolean, compu {phys=raw for raw 0}, transfer-property=PENDING  # ASR NM Control Bit Vector - Repeat Message Request
          signal ISignal_BCAN_NM_SGU_FD_CBV_NMCoID_SGU_FD: start 9, 2 bit, little-endian, init-value=0, base-type=uint8, compu {phys=raw for raw 0}, transfer-property=PENDING  # ASR NM Control Bit Vector - ASR NM Coordinator ID
          signal ISignal_BCAN_NM_SGU_FD_CBV_NMCoSRB_SGU_FD: start 11, 1 bit, little-endian, init-value=0, base-type=boolean, compu {phys=raw for raw 0}, transfer-property=PENDING  # ASR NM Control Bit Vector - ASR NM Coordinator Sleep Ready Bit
          signal ISignal_BCAN_NM_SGU_FD_CBV_AWB_SGU_FD: start 12, 1 bit, little-endian, init-value=0, base-type=boolean, compu {phys=raw for raw 0}, transfer-property=PENDING  # ASR NM Control Bit Vector - Active Wakeup Bit
          signal ISignal_BCAN_NM_SGU_FD_CBV_PNIB_SGU_FD: start 14, 1 bit, little-endian, init-value=0, base-type=boolean, compu {phys=raw for raw 0}, transfer-property=PENDING  # ASR NM Control Bit Vector - PN Info Bit
          signal ISignal_BCAN_NM_SGU_FD_NRR_SGU_FD: start 16, 8 bit, little-endian, init-value=0, base-type=uint8, compu {phys=raw for raw 0}, transfer-property=PENDING  # ASR NM Network Request Reason
          signal ISignal_BCAN_NM_SGU_FD_NM_State_SGU_FD: start 24, 8 bit, little-endian, init-value=0, base-type=uint8, compu {phys=raw for raw 0}, transfer-property=PENDING  # ASR NM State_Current State_Previous State
          signal ISignal_BCAN_NM_SGU_FD_PNI_SGU_FD: start 32, 32 bit, little-endian, init-value=0, base-type=uint32, compu {phys=raw for raw 0}, transfer-property=PENDING  # ASR NM Partial Networking Information
          signal ISignal_BCAN_NM_SGU_FD_PNI_SGU_FD_1: start 64, 64 bit, opaque, init-value=8 x 0, compu {phys=raw for raw 0}, implementation-data-type=array8uint8, transfer-property=PENDING  # ASR NM Partial Networking Information
          signal ISignal_BCAN_NM_SGU_FD_PNI_SGU_FD_2: start 128, 64 bit, opaque, init-value=8 x 0, compu {phys=raw for raw 0}, implementation-data-type=array8uint8, transfer-property=PENDING  # ASR NM Partial Networking Information
          signal ISignal_BCAN_NM_SGU_FD_PNI_SGU_FD_3: start 192, 64 bit, opaque, init-value=8 x 0, compu {phys=raw for raw 0}, implementation-data-type=array8uint8, transfer-property=PENDING  # ASR NM Partial Networking Information
      frame CanFrame_BCAN_NM_DCM_FD: id 0x17FC0029, frame-length=32, can-addressing-mode=EXTENDED, can-fd-frame-support=true
        nm pdu NmPdu_BCAN_NM_DCM_FD: length=32
          signal ISignal_BCAN_NM_DCM_FD_SNI_DCM_FD: start 0, 8 bit, little-endian, init-value=0, base-type=uint8, compu {phys=raw for raw 0}, transfer-property=PENDING  # ASR NM Source Node Identifier
          signal ISignal_BCAN_NM_DCM_FD_CBV_RMR_DCM_FD: start 8, 1 bit, little-endian, init-value=0, base-type=boolean, compu {phys=raw for raw 0}, transfer-property=PENDING  # ASR NM Control Bit Vector - Repeat Message Request
          signal ISignal_BCAN_NM_DCM_FD_CBV_NMCoID_DCM_FD: start 9, 2 bit, little-endian, init-value=0, base-type=uint8, compu {phys=raw for raw 0}, transfer-property=PENDING  # ASR NM Control Bit Vector - ASR NM Coordinator ID
          signal ISignal_BCAN_NM_DCM_FD_CBV_NMCoSRB_DCM_FD: start 11, 1 bit, little-endian, init-value=0, base-type=boolean, compu {phys=raw for raw 0}, transfer-property=PENDING  # ASR NM Control Bit Vector - ASR NM Coordinator Sleep Ready Bit
          signal ISignal_BCAN_NM_DCM_FD_CBV_AWB_DCM_FD: start 12, 1 bit, little-endian, init-value=0, base-type=boolean, compu {phys=raw for raw 0}, transfer-property=PENDING  # ASR NM Control Bit Vector - Active Wakeup Bit
          signal ISignal_BCAN_NM_DCM_FD_CBV_PNIB_DCM_FD: start 14, 1 bit, little-endian, init-value=0, base-type=boolean, compu {phys=raw for raw 0}, transfer-property=PENDING  # ASR NM Control Bit Vector - PN Info Bit
          signal ISignal_BCAN_NM_DCM_FD_NRR_DCM_FD: start 16, 8 bit, little-endian, init-value=0, base-type=uint8, compu {phys=raw for raw 0}, transfer-property=PENDING  # ASR NM Network Request Reason
          signal ISignal_BCAN_NM_DCM_FD_NM_State_DCM_FD: start 24, 8 bit, little-endian, init-value=0, base-type=uint8, compu {phys=raw for raw 0}, transfer-property=PENDING  # ASR NM State_Current State_Previous State
          signal ISignal_BCAN_NM_DCM_FD_PNI_DCM_FD: start 32, 32 bit, little-endian, init-value=0, base-type=uint32, compu {phys=raw for raw 0}, transfer-property=PENDING  # ASR NM Partial Networking Information
          signal ISignal_BCAN_NM_DCM_FD_PNI_DCM_FD_1: start 64, 64 bit, opaque, init-value=8 x 0, compu {phys=raw for raw 0}, implementation-data-type=array8uint8, transfer-property=PENDING  # ASR NM Partial Networking Information
          signal ISignal_BCAN_NM_DCM_FD_PNI_DCM_FD_2: start 128, 64 bit, opaque, init-value=8 x 0, compu {phys=raw for raw 0}, implementation-data-type=array8uint8, transfer-property=PENDING  # ASR NM Partial Networking Information
          signal ISignal_BCAN_NM_DCM_FD_PNI_DCM_FD_3: start 192, 64 bit, opaque, init-value=8 x 0, compu {phys=raw for raw 0}, implementation-data-type=array8uint8, transfer-property=PENDING  # ASR NM Partial Networking Information
package /DBCImport/COMPUMETHODS
  compu method ISignal_BCAN_IAU_FD_04_200ms_IAU_ProfileIDRVal: 0=Default, 1=Guest, 2..10=Profile1..Profile9, 11..14=RESERVED, 15=INVALID, phys=raw for raw 0
package /DBCImport/IPDUGROUPS
  6 x i signal i pdu group:
    ISignalIPduGroupRx_WPC_BCAN_PNC141: communication-direction=IN, communication-mode=rx
      i-signal-i-pdus:
        ISignalIPdu_BCAN_VCU_01_10ms
        ISignalIPdu_BCAN_BDC_FD_SMK_02_200ms
        ISignalIPdu_BCAN_CLU_05_00ms
        ISignalIPdu_BCAN_CLU_09_00ms
        ISignalIPdu_BCAN_PDC_FD_15_300ms
        ISignalIPdu_BCAN_HCU_03_10ms
        ISignalIPdu_BCAN_HU_USM_02_00ms
        ISignalIPdu_BCAN_HU_USM_01_00ms
        ISignalIPdu_BCAN_HU_USM_05_00ms
        ISignalIPdu_BCAN_HU_USM_04_00ms
        ISignalIPdu_BCAN_SBCM_RR_FD_01_200ms
        ISignalIPdu_BCAN_SBCM_RL_FD_01_200ms
        ISignalIPdu_BCAN_EMS_02_10ms
        ISignalIPdu_BCAN_EMS_07_10ms
        ISignalIPdu_BCAN_SBCM_DRV_FD_01_200ms
        ISignalIPdu_BCAN_SBCM_AST_FD_01_200ms
        ISignalIPdu_BCAN_CLU_20_200ms
        ISignalIPdu_BCAN_RWPC_FD_01_200ms
        ISignalIPdu_BCAN_HU_GW_03_200ms
        ISignalIPdu_BCAN_IAU_FD_04_200ms
        ISignalIPdu_BCAN_CLU_01_20ms
        ISignalIPdu_BCAN_PDC_FD_03_200ms
        ISignalIPdu_BCAN_BDC_FD_02_200ms
        ISignalIPdu_BCAN_BDC_FD_05_200ms
    ISignalIPduGroupRx_WPC_BCAN_PNC153: communication-direction=IN, communication-mode=rx
      i-signal-i-pdus:
        ISignalIPdu_BCAN_VCU_01_10ms
        ISignalIPdu_BCAN_BDC_FD_SMK_02_200ms
        ISignalIPdu_BCAN_CLU_05_00ms
        ISignalIPdu_BCAN_CLU_09_00ms
        ISignalIPdu_BCAN_PDC_FD_15_300ms
        ISignalIPdu_BCAN_HCU_03_10ms
        ISignalIPdu_BCAN_HU_USM_02_00ms
        ISignalIPdu_BCAN_HU_USM_01_00ms
        ISignalIPdu_BCAN_HU_USM_05_00ms
        ISignalIPdu_BCAN_HU_USM_04_00ms
        ISignalIPdu_BCAN_SBCM_RR_FD_01_200ms
        ISignalIPdu_BCAN_SBCM_RL_FD_01_200ms
        ISignalIPdu_BCAN_EMS_02_10ms
        ISignalIPdu_BCAN_EMS_07_10ms
        ISignalIPdu_BCAN_SBCM_DRV_FD_01_200ms
        ISignalIPdu_BCAN_SBCM_AST_FD_01_200ms
        ISignalIPdu_BCAN_CLU_20_200ms
        ISignalIPdu_BCAN_RWPC_FD_01_200ms
        ISignalIPdu_BCAN_HU_GW_03_200ms
        ISignalIPdu_BCAN_IAU_FD_04_200ms
        ISignalIPdu_BCAN_CLU_01_20ms
        ISignalIPdu_BCAN_PDC_FD_03_200ms
        ISignalIPdu_BCAN_BDC_FD_02_200ms
        ISignalIPdu_BCAN_BDC_FD_05_200ms
    ISignalIPduGroupRx_WPC_BCAN_PNC32: communication-direction=IN, communication-mode=rx
      i-signal-i-pdus:
        ISignalIPdu_BCAN_VCU_01_10ms
        ISignalIPdu_BCAN_BDC_FD_SMK_02_200ms
        ISignalIPdu_BCAN_CLU_05_00ms
        ISignalIPdu_BCAN_CLU_09_00ms
        ISignalIPdu_BCAN_PDC_FD_15_300ms
        ISignalIPdu_BCAN_HCU_03_10ms
        ISignalIPdu_BCAN_HU_USM_02_00ms
        ISignalIPdu_BCAN_HU_USM_01_00ms
        ISignalIPdu_BCAN_HU_USM_05_00ms
        ISignalIPdu_BCAN_HU_USM_04_00ms
        ISignalIPdu_BCAN_SBCM_RR_FD_01_200ms
        ISignalIPdu_BCAN_SBCM_RL_FD_01_200ms
        ISignalIPdu_BCAN_EMS_02_10ms
        ISignalIPdu_BCAN_EMS_07_10ms
        ISignalIPdu_BCAN_SBCM_DRV_FD_01_200ms
        ISignalIPdu_BCAN_SBCM_AST_FD_01_200ms
        ISignalIPdu_BCAN_CLU_20_200ms
        ISignalIPdu_BCAN_RWPC_FD_01_200ms
        ISignalIPdu_BCAN_HU_GW_03_200ms
        ISignalIPdu_BCAN_IAU_FD_04_200ms
        ISignalIPdu_BCAN_CLU_01_20ms
        ISignalIPdu_BCAN_PDC_FD_03_200ms
        ISignalIPdu_BCAN_BDC_FD_02_200ms
        ISignalIPdu_BCAN_BDC_FD_05_200ms
    ISignalIPduGroupTx_WPC_BCAN_PNC141: communication-direction=OUT, communication-mode=tx
      i-signal-i-pdus:
        ISignalIPdu_BCAN_WPCmsgDvp1
        ISignalIPdu_BCAN_WPC_FD_VCRM_01_00ms
        ISignalIPdu_BCAN_WPC_WU_01_500ms
        ISignalIPdu_BCAN_WPC2_FD_01_200ms
        ISignalIPdu_BCAN_WPC_FD_01_200ms
    ISignalIPduGroupTx_WPC_BCAN_PNC153: communication-direction=OUT, communication-mode=tx
      i-signal-i-pdus:
        ISignalIPdu_BCAN_WPCmsgDvp1
        ISignalIPdu_BCAN_WPC_FD_VCRM_01_00ms
        ISignalIPdu_BCAN_WPC_WU_01_500ms
        ISignalIPdu_BCAN_WPC2_FD_01_200ms
        ISignalIPdu_BCAN_WPC_FD_01_200ms
    ISignalIPduGroupTx_WPC_BCAN_PNC32: communication-direction=OUT, communication-mode=tx
      i-signal-i-pdus:
        ISignalIPdu_BCAN_WPCmsgDvp1
        ISignalIPdu_BCAN_WPC_FD_VCRM_01_00ms
        ISignalIPdu_BCAN_WPC_WU_01_500ms
        ISignalIPdu_BCAN_WPC2_FD_01_200ms
        ISignalIPdu_BCAN_WPC_FD_01_200ms
package /DBCImport/INTERFACES
  29 x sender receiver interface:
    BCAN_BDC_FD_02_200ms
      data BCM_SmkOptTyp: base-type=uint8, compu {phys=raw for raw 0}, type=uint8, init-value=0
    BCAN_BDC_FD_05_200ms
      data Lamp_IntTailLmpOnReq: base-type=uint8, compu {phys=raw for raw 0}, type=uint8, init-value=0
    BCAN_BDC_FD_SMK_02_200ms
      data LFAnt_SrchSta: base-type=uint8, compu {phys=raw for raw 0}, type=uint8, init-value=0
    BCAN_CLU_01_20ms
      4 x data, all with init-value=0:
        CLU_DtntOutSta: base-type=uint8, compu {phys=raw for raw 0}, type=uint8
        CLU_RhstaLvlSta: base-type=uint8, compu {phys=raw for raw 0}, type=uint8
        CLU_DisSpdVal_KPH: base-type=uint16, compu {511=Error, phys=raw for raw 0; unit km/h}, unit=km/h, type=uint16
        CLU_AutoBrightSta: base-type=uint8, compu {phys=raw for raw 0}, type=uint8
    BCAN_CLU_05_00ms
      data USM_StaRst1Req: base-type=uint8, compu {phys=raw for raw 0}, type=uint8, init-value=0
    BCAN_CLU_09_00ms
      data USM_WpcSetReq: base-type=uint8, compu {phys=raw for raw 0}, type=uint8, init-value=0
    BCAN_CLU_20_200ms
      data CLU_ClusterUSM: base-type=uint8, compu {phys=raw for raw 0}, type=uint8, init-value=0
    BCAN_EMS_02_10ms
      data ENG_EngSta: base-type=uint8, compu {phys=raw for raw 0}, type=uint8, init-value=0
    BCAN_EMS_07_10ms
      data HEV_EngOpSta: base-type=uint8, compu {phys=raw for raw 0}, type=uint8, init-value=0
    BCAN_HCU_03_10ms
      data HCU_HevRdySta: base-type=uint8, compu {phys=raw for raw 0}, type=uint8, init-value=0
    BCAN_HU_GW_03_200ms
      data CF_AVN_ProfileIDRValue: base-type=uint8, compu {phys=raw for raw 0}, type=uint8, init-value=15
    BCAN_HU_USM_01_00ms
      data CF_Gway_WPCNValueSet: base-type=uint8, compu {phys=raw for raw 0}, type=uint8, init-value=0
    BCAN_HU_USM_02_00ms
      data CF_AVN_CluUSMReset: base-type=uint8, compu {phys=raw for raw 0}, type=uint8, init-value=0
    BCAN_HU_USM_04_00ms
      data CF_Gway_WPC2_NValueSet: base-type=uint8, compu {phys=raw for raw 0}, type=uint8, init-value=0
    BCAN_HU_USM_05_00ms
      data CF_Gway_WPCAnimationNvalueSet: base-type=uint8, compu {phys=raw for raw 0}, type=uint8, init-value=0
    BCAN_IAU_FD_04_200ms
      data IAU_DigitalKey2Opt: base-type=uint8, compu {phys=raw for raw 0}, type=uint8, init-value=0
      data IAU_ProfileIDRVal: base-type=uint8, compu-method=ISignal_BCAN_IAU_FD_04_200ms_IAU_ProfileIDRVal, type=uint8, init-value=0
    BCAN_PDC_FD_03_200ms
      4 x data, all with base-type=uint8, compu {phys=raw for raw 0}, type=uint8, init-value=0:
        Warn_DrvDrSwSta
        Warn_AsstDrSwSta
        Warn_RrLftDrSwSta
        Warn_RrRtDrSwSta
    BCAN_RWPC_FD_01_200ms
      data RWPC_IndSyncVal: base-type=uint8, compu {phys=raw for raw 0}, type=uint8, init-value=0
    BCAN_SBCM_AST_FD_01_200ms
      data Warn_AsstDrSwSta_SBCM: base-type=uint8, compu {phys=raw for raw 0}, type=uint8, init-value=0
    BCAN_SBCM_DRV_FD_01_200ms
      data Latch_TypeOption_DRV: base-type=uint8, compu {phys=raw for raw 0}, type=uint8, init-value=0
      data Warn_DrvDrSwSta_SBCM: base-type=uint8, compu {phys=raw for raw 0}, type=uint8, init-value=0
    BCAN_SBCM_RL_FD_01_200ms
      data Warn_RrLftDrSwSta_SBCM: base-type=uint8, compu {phys=raw for raw 0}, type=uint8, init-value=0
    BCAN_SBCM_RR_FD_01_200ms
      data Warn_RrRtDrSwSta_SBCM: base-type=uint8, compu {phys=raw for raw 0}, type=uint8, init-value=0
    BCAN_VCU_01_10ms
      data VCU_EvDrvRdySta: base-type=uint8, compu {phys=raw for raw 0..3}, type=uint8, init-value=0
      data VCU_GearPosSta: base-type=uint8, compu {phys=raw for raw 0..15}, type=uint8, init-value=9
    BCAN_WPCmsgDvp1
      64 x data, all with base-type=uint8, compu {phys=raw for raw 0}, type=uint8, init-value=0:
        WPCmsgDvp1DataByte63
        WPCmsgDvp1DataByte62
        WPCmsgDvp1DataByte61
        WPCmsgDvp1DataByte60
        WPCmsgDvp1DataByte59
        WPCmsgDvp1DataByte58
        WPCmsgDvp1DataByte57
        WPCmsgDvp1DataByte56
        WPCmsgDvp1DataByte55
        WPCmsgDvp1DataByte54
        WPCmsgDvp1DataByte53
        WPCmsgDvp1DataByte52
        WPCmsgDvp1DataByte51
        WPCmsgDvp1DataByte50
        WPCmsgDvp1DataByte49
        WPCmsgDvp1DataByte48
        WPCmsgDvp1DataByte47
        WPCmsgDvp1DataByte46
        WPCmsgDvp1DataByte45
        WPCmsgDvp1DataByte44
        WPCmsgDvp1DataByte43
        WPCmsgDvp1DataByte42
        WPCmsgDvp1DataByte41
        WPCmsgDvp1DataByte40
        WPCmsgDvp1DataByte39
        WPCmsgDvp1DataByte38
        WPCmsgDvp1DataByte37
        WPCmsgDvp1DataByte36
        WPCmsgDvp1DataByte35
        WPCmsgDvp1DataByte34
        WPCmsgDvp1DataByte33
        WPCmsgDvp1DataByte32
        WPCmsgDvp1DataByte31
        WPCmsgDvp1DataByte30
        WPCmsgDvp1DataByte29
        WPCmsgDvp1DataByte28
        WPCmsgDvp1DataByte27
        WPCmsgDvp1DataByte26
        WPCmsgDvp1DataByte25
        WPCmsgDvp1DataByte24
        WPCmsgDvp1DataByte23
        WPCmsgDvp1DataByte22
        WPCmsgDvp1DataByte21
        WPCmsgDvp1DataByte20
        WPCmsgDvp1DataByte19
        WPCmsgDvp1DataByte18
        WPCmsgDvp1DataByte17
        WPCmsgDvp1DataByte16
        WPCmsgDvp1DataByte15
        WPCmsgDvp1DataByte14
        WPCmsgDvp1DataByte13
        WPCmsgDvp1DataByte12
        WPCmsgDvp1DataByte11
        WPCmsgDvp1DataByte10
        WPCmsgDvp1DataByte09
        WPCmsgDvp1DataByte08
        WPCmsgDvp1DataByte07
        WPCmsgDvp1DataByte06
        WPCmsgDvp1DataByte05
        WPCmsgDvp1DataByte04
        WPCmsgDvp1DataByte03
        WPCmsgDvp1DataByte02
        WPCmsgDvp1DataByte01
        WPCmsgDvp1DataByte00
    Gr_MsgGr_E2E_BCAN_PDC_FD_15_300ms
      data MsgGr_E2E_BCAN_PDC_FD_15_300ms: type=MsgGr_E2E_BCAN_PDC_FD_15_300ms, init-value=fields=[0, 0, 0, 0]
    Gr_MsgGr_E2E_BCAN_WPC2_FD_01_200ms
      data MsgGr_E2E_BCAN_WPC2_FD_01_200ms: type=MsgGr_E2E_BCAN_WPC2_FD_01_200ms, init-value=fields=[0, 0, 0, 0, 0, 0, 0, 0, 0]
    Gr_MsgGr_E2E_BCAN_WPC_FD_01_200ms
      data MsgGr_E2E_BCAN_WPC_FD_01_200ms: type=MsgGr_E2E_BCAN_WPC_FD_01_200ms, init-value=fields=[0, 0, 0, 0, 0, 0, 0, 2, 0, 0]
    Gr_MsgGr_E2E_BCAN_WPC_FD_VCRM_01_00ms
      data MsgGr_E2E_BCAN_WPC_FD_VCRM_01_00ms: type=MsgGr_E2E_BCAN_WPC_FD_VCRM_01_00ms, init-value=fields=[0, 0, 0, 0, 0, 0, 0, 0, 0, 0, 0, 0, 0, 0]
    Gr_MsgGr_E2E_BCAN_WPC_WU_01_500ms
      data MsgGr_E2E_BCAN_WPC_WU_01_500ms: type=MsgGr_E2E_BCAN_WPC_WU_01_500ms, init-value=fields=[0, 0, 0, 0, 0, 0, 0, 0, 0, 0]
package /DBCImport/ISIGNALGROUPS
  5 x i signal group:
    MsgGr_E2E_BCAN_PDC_FD_15_300ms:
      com-based-signal-group-transformations=XfRx_BCAN_P5
      i-signal=[ISignal_BCAN_PDC_FD_15_300ms_PDC_FD_Crc15Val, ISignal_BCAN_PDC_FD_15_300ms_PDC_FD_AlvCnt15Val, ISignal_BCAN_PDC_FD_15_300ms_PDC_ResetPreWrngForOthers, ISignal_BCAN_PDC_FD_15_300ms_PDC_ResetReqForOthers, ISignal_BCAN_PDC_FD_15_300ms_PDC_ResetFuncOpt, ISignal_BCAN_PDC_FD_15_300ms_PDC_FD_15_300ms_E2EReserved]
      system-signal-group=MsgGr_E2E_BCAN_PDC_FD_15_300ms
      end-to-end-transformation-i-signal-props{transformer=XfTechRx_E2EXf_P5, data-ids=64233, data-length=256}
    MsgGr_E2E_BCAN_WPC2_FD_01_200ms:
      com-based-signal-group-transformations=XfTx_BCAN_P5
      i-signal=[ISignal_BCAN_WPC2_FD_01_200ms_WPC2_FD_Crc1Val, ISignal_BCAN_WPC2_FD_01_200ms_WPC2_FD_AlvCnt1Val, ISignal_BCAN_WPC2_FD_01_200ms_USM_CmdWPC2Sta, ISignal_BCAN_WPC2_FD_01_200ms_WPC2_PhnLftWrngSta, ISignal_BCAN_WPC2_FD_01_200ms_WPC2_OptSta, ISignal_BCAN_WPC2_FD_01_200ms_WPC2_SWVerMajor1, ISignal_BCAN_WPC2_FD_01_200ms_WPC2_SWVerMinor1, ISignal_BCAN_WPC2_FD_01_200ms_WPC2_SWVerMinor2, ISignal_BCAN_WPC2_FD_01_200ms_WPC2_IndSyncVal, ISignal_BCAN_WPC2_FD_01_200ms_WPC2_ResetOpSta, ISignal_BCAN_WPC2_FD_01_200ms_WPC2_FD_01_200ms_E2EReserved]
      system-signal-group=MsgGr_E2E_BCAN_WPC2_FD_01_200ms
      end-to-end-transformation-i-signal-props{transformer=XfTechTx_E2EXf_P5, data-ids=64402, data-length=128}
    MsgGr_E2E_BCAN_WPC_FD_01_200ms:
      com-based-signal-group-transformations=XfTx_BCAN_P5
      i-signal=[ISignal_BCAN_WPC_FD_01_200ms_WPC_FD_Crc1Val, ISignal_BCAN_WPC_FD_01_200ms_WPC_FD_AlvCnt1Val, ISignal_BCAN_WPC_FD_01_200ms_USM_CmdWPCSta, ISignal_BCAN_WPC_FD_01_200ms_WPC_PhnLftWrngSta, ISignal_BCAN_WPC_FD_01_200ms_WPC_DualWPCOptSta, ISignal_BCAN_WPC_FD_01_200ms_WPC_SWVerMajor1, ISignal_BCAN_WPC_FD_01_200ms_WPC_SWVerMinor1, ISignal_BCAN_WPC_FD_01_200ms_WPC_SWVerMinor2, ISignal_BCAN_WPC_FD_01_200ms_WPC_IndSyncVal, ISignal_BCAN_WPC_FD_01_200ms_USM_CmdWPCIndSta, ISignal_BCAN_WPC_FD_01_200ms_WPC_ResetOpSta, ISignal_BCAN_WPC_FD_01_200ms_WPC_FD_01_200ms_E2EReserved]
      system-signal-group=MsgGr_E2E_BCAN_WPC_FD_01_200ms
      end-to-end-transformation-i-signal-props{transformer=XfTechTx_E2EXf_P5, data-ids=64401, data-length=128}
    MsgGr_E2E_BCAN_WPC_FD_VCRM_01_00ms:
      com-based-signal-group-transformations=XfTx_BCAN_P5
      i-signal=[ISignal_BCAN_WPC_FD_VCRM_01_00ms_WPC_FD_VCRM_Crc1Val, ISignal_BCAN_WPC_FD_VCRM_01_00ms_WPC_FD_VCRM_AlvCnt1Val, ISignal_BCAN_WPC_FD_VCRM_01_00ms_WPC_PhnUsingTime, ISignal_BCAN_WPC_FD_VCRM_01_00ms_WPC_PhnChargingCompleteCnt, ISignal_BCAN_WPC_FD_VCRM_01_00ms_WPC_EPPChargingCnt, ISignal_BCAN_WPC_FD_VCRM_01_00ms_WPC_MPPChargingCnt, ISignal_BCAN_WPC_FD_VCRM_01_00ms_WPC_DigitalKeyAuth, ISignal_BCAN_WPC_FD_VCRM_01_00ms_WPC_DigitalKeyDevice, ISignal_BCAN_WPC_FD_VCRM_01_00ms_WPC_PhnChargingErrCnt, ISignal_BCAN_WPC_FD_VCRM_01_00ms_WPC_ThermalSnsrMaxTemp, ISignal_BCAN_WPC_FD_VCRM_01_00ms_WPC_CANBusOffDTC, ISignal_BCAN_WPC_FD_VCRM_01_00ms_WPC_LocalCANBusOffDTC, ISignal_BCAN_WPC_FD_VCRM_01_00ms_WPC_TempSnsrFltDTC, ISignal_BCAN_WPC_FD_VCRM_01_00ms_WPC_FANFltDTC, ISignal_BCAN_WPC_FD_VCRM_01_00ms_WPC_InternalECUErrDTC, ISignal_BCAN_WPC_FD_VCRM_01_00ms_WPC_FD_VCRM_01_00ms_E2EReserved]
      system-signal-group=MsgGr_E2E_BCAN_WPC_FD_VCRM_01_00ms
      end-to-end-transformation-i-signal-props{transformer=XfTechTx_E2EXf_P5, data-ids=64031, data-length=128}
    MsgGr_E2E_BCAN_WPC_WU_01_500ms:
      com-based-signal-group-transformations=XfTx_BCAN_P5
      i-signal=[ISignal_BCAN_WPC_WU_01_500ms_WPC_WU_Crc1Val, ISignal_BCAN_WPC_WU_01_500ms_WPC_WU_AlvCnt1Val, ISignal_BCAN_WPC_WU_01_500ms_WPC_WU_NM_B2, ISignal_BCAN_WPC_WU_01_500ms_WPC_WU_NM_BDCLocal, ISignal_BCAN_WPC_WU_01_500ms_WPC_WU_PWR_ACC, ISignal_BCAN_WPC_WU_01_500ms_WPC_WU_PWR_IGN1, ISignal_BCAN_WPC_WU_01_500ms_WPC_WU_R_DrvDoorSw, ISignal_BCAN_WPC_WU_01_500ms_WPC_WU_R_B1CAN, ISignal_BCAN_WPC_WU_01_500ms_WPC_WU_R_BDCLocalCAN, ISignal_BCAN_WPC_WU_01_500ms_WPC_WU_R_Diag, ISignal_BCAN_WPC_WU_01_500ms_WPC_WU_R_IGNFallingTimer, ISignal_BCAN_WPC_WU_01_500ms_WPC_WU_01_500ms_E2EReserved]
      system-signal-group=MsgGr_E2E_BCAN_WPC_WU_01_500ms
      end-to-end-transformation-i-signal-props{transformer=XfTechTx_E2EXf_P5, data-ids=65456, data-length=128}
package /DBCImport/UNITS_BCAN
  unit Unit_Min: display-name=Min
  unit Unit_km_per_h: display-name=km/h
package /DBCImport/ImplementationDataTypes_BCAN
  6 x impl type:
    MsgGr_E2E_BCAN_PDC_FD_15_300ms: category=STRUCTURE
      4 x element, all with category=TYPE_REFERENCE, implementation-data-type=uint8:
        PDC_ResetPreWrngForOthers
        PDC_ResetReqForOthers
        PDC_ResetFuncOpt
        PDC_FD_15_300ms_E2EReserved
    MsgGr_E2E_BCAN_WPC2_FD_01_200ms: category=STRUCTURE
      9 x element, all with category=TYPE_REFERENCE, implementation-data-type=uint8:
        USM_CmdWPC2Sta
        WPC2_PhnLftWrngSta
        WPC2_OptSta
        WPC2_SWVerMajor1
        WPC2_SWVerMinor1
        WPC2_SWVerMinor2
        WPC2_IndSyncVal
        WPC2_ResetOpSta
        WPC2_FD_01_200ms_E2EReserved
    MsgGr_E2E_BCAN_WPC_FD_01_200ms: category=STRUCTURE
      10 x element, all with category=TYPE_REFERENCE, implementation-data-type=uint8:
        USM_CmdWPCSta
        WPC_PhnLftWrngSta
        WPC_DualWPCOptSta
        WPC_SWVerMajor1
        WPC_SWVerMinor1
        WPC_SWVerMinor2
        WPC_IndSyncVal
        USM_CmdWPCIndSta
        WPC_ResetOpSta
        WPC_FD_01_200ms_E2EReserved
    MsgGr_E2E_BCAN_WPC_FD_VCRM_01_00ms: category=STRUCTURE
      14 x element, all with category=TYPE_REFERENCE:
        WPC_PhnUsingTime: implementation-data-type=uint8
        WPC_PhnChargingCompleteCnt: implementation-data-type=uint8
        WPC_EPPChargingCnt: implementation-data-type=uint8
        WPC_MPPChargingCnt: implementation-data-type=uint8
        WPC_DigitalKeyAuth: implementation-data-type=boolean
        WPC_DigitalKeyDevice: implementation-data-type=uint8
        WPC_PhnChargingErrCnt: implementation-data-type=uint8
        WPC_ThermalSnsrMaxTemp: implementation-data-type=uint8
        WPC_CANBusOffDTC: implementation-data-type=uint8
        WPC_LocalCANBusOffDTC: implementation-data-type=uint8
        WPC_TempSnsrFltDTC: implementation-data-type=uint8
        WPC_FANFltDTC: implementation-data-type=uint8
        WPC_InternalECUErrDTC: implementation-data-type=uint8
        WPC_FD_VCRM_01_00ms_E2EReserved: implementation-data-type=uint8
    MsgGr_E2E_BCAN_WPC_WU_01_500ms: category=STRUCTURE
      10 x element, all with category=TYPE_REFERENCE:
        WPC_WU_NM_B2: implementation-data-type=boolean
        WPC_WU_NM_BDCLocal: implementation-data-type=boolean
        WPC_WU_PWR_ACC: implementation-data-type=boolean
        WPC_WU_PWR_IGN1: implementation-data-type=boolean
        WPC_WU_R_DrvDoorSw: implementation-data-type=boolean
        WPC_WU_R_B1CAN: implementation-data-type=boolean
        WPC_WU_R_BDCLocalCAN: implementation-data-type=boolean
        WPC_WU_R_Diag: implementation-data-type=boolean
        WPC_WU_R_IGNFallingTimer: implementation-data-type=boolean
        WPC_WU_01_500ms_E2EReserved: implementation-data-type=uint8
    array8uint8: category=ARRAY
      element uint8: array-size=8, array-size-semantics=FIXED-SIZE, implementation-data-type=uint8
